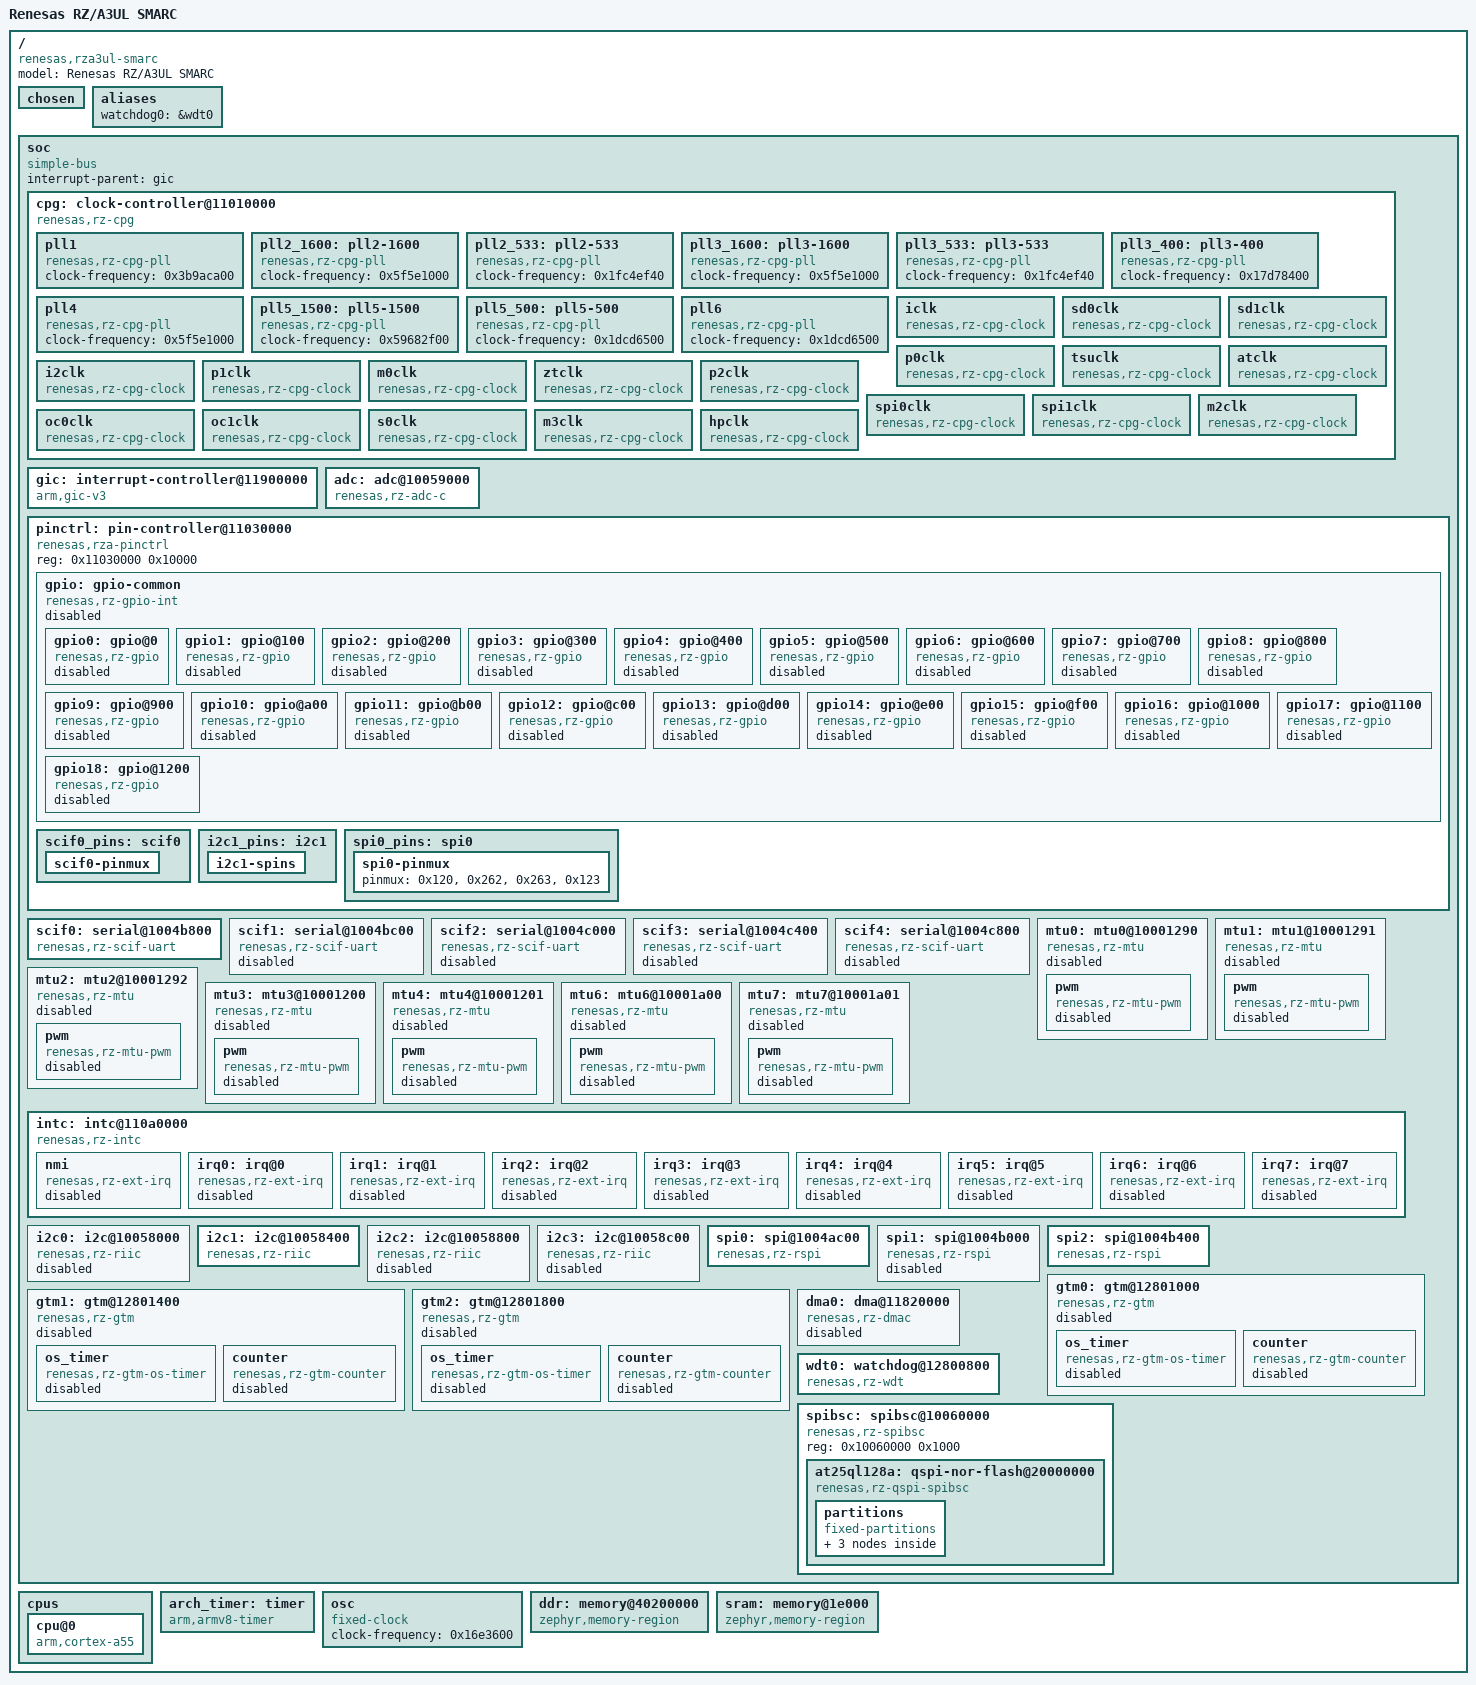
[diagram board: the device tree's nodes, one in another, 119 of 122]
/dts-v1/;

/* node '/' defined in zephyr/dts/common/skeleton.dtsi:9 */
/ {
	#address-cells = < 0x1 >;            /* in zephyr/dts/arm64/renesas/rz/rza/r9a07g063.dtsi:19 */
	#size-cells = < 0x1 >;               /* in zephyr/dts/arm64/renesas/rz/rza/r9a07g063.dtsi:20 */
	model = "Renesas RZ/A3UL SMARC";     /* in zephyr/boards/renesas/rza3ul_smarc/rza3ul_smarc.dts:16 */
	compatible = "renesas,rza3ul-smarc"; /* in zephyr/boards/renesas/rza3ul_smarc/rza3ul_smarc.dts:17 */

	/* node '/chosen' defined in zephyr/dts/common/skeleton.dtsi:13 */
	chosen {
		zephyr,sram = &ddr;                       /* in zephyr/boards/renesas/rza3ul_smarc/rza3ul_smarc.dts:20 */
		zephyr,flash = &at25ql128a;               /* in zephyr/boards/renesas/rza3ul_smarc/rza3ul_smarc.dts:21 */
		zephyr,console = &scif0;                  /* in zephyr/boards/renesas/rza3ul_smarc/rza3ul_smarc.dts:22 */
		zephyr,shell-uart = &scif0;               /* in zephyr/boards/renesas/rza3ul_smarc/rza3ul_smarc.dts:23 */
		zephyr,code-partition = &slot0_partition; /* in zephyr/boards/renesas/rza3ul_smarc/rza3ul_smarc.dts:24 */
	};

	/* node '/aliases' defined in zephyr/dts/common/skeleton.dtsi:15 */
	aliases {
		watchdog0 = &wdt0; /* in zephyr/boards/renesas/rza3ul_smarc/rza3ul_smarc.dts:28 */
	};

	/* node '/soc' defined in zephyr/dts/arm64/armv8-a.dtsi:10 */
	soc {
		#address-cells = < 0x1 >;    /* in zephyr/dts/arm64/armv8-a.dtsi:11 */
		#size-cells = < 0x1 >;       /* in zephyr/dts/arm64/armv8-a.dtsi:12 */
		compatible = "simple-bus";   /* in zephyr/dts/arm64/armv8-a.dtsi:13 */
		ranges;                      /* in zephyr/dts/arm64/armv8-a.dtsi:14 */
		interrupt-parent = < &gic >; /* in zephyr/dts/arm64/renesas/rz/rza/r9a07g063.dtsi:50 */

		/* node '/soc/clock-controller@11010000' defined in zephyr/dts/arm64/renesas/rz/rza/r9a07g063.dtsi:52 */
		cpg: clock-controller@11010000 {
			compatible = "renesas,rz-cpg"; /* in zephyr/dts/arm64/renesas/rz/rza/r9a07g063.dtsi:53 */
			reg = < 0x11010000 0x10000 >;  /* in zephyr/dts/arm64/renesas/rz/rza/r9a07g063.dtsi:54 */
			clocks = < &osc >;             /* in zephyr/dts/arm64/renesas/rz/rza/r9a07g063.dtsi:55 */
			#clock-cells = < 0x1 >;        /* in zephyr/dts/arm64/renesas/rz/rza/r9a07g063.dtsi:56 */
			status = "okay";               /* in zephyr/dts/arm64/renesas/rz/rza/r9a07g063.dtsi:57 */

			/* node '/soc/clock-controller@11010000/pll1' defined in zephyr/dts/arm64/renesas/rz/rza/r9a07g063.dtsi:59 */
			pll1: pll1 {
				compatible = "renesas,rz-cpg-pll"; /* in zephyr/dts/arm64/renesas/rz/rza/r9a07g063.dtsi:60 */
				clock-frequency = < 0x3b9aca00 >;  /* in zephyr/dts/arm64/renesas/rz/rza/r9a07g063.dtsi:61 */
				#clock-cells = < 0x1 >;            /* in zephyr/dts/arm64/renesas/rz/rza/r9a07g063.dtsi:62 */
				phandle = < 0x3 >;                 /* in zephyr/dts/arm64/renesas/rz/rza/r9a07g063.dtsi:121 */
			};

			/* node '/soc/clock-controller@11010000/pll2-1600' defined in zephyr/dts/arm64/renesas/rz/rza/r9a07g063.dtsi:65 */
			pll2_1600: pll2-1600 {
				compatible = "renesas,rz-cpg-pll"; /* in zephyr/dts/arm64/renesas/rz/rza/r9a07g063.dtsi:66 */
				clock-frequency = < 0x5f5e1000 >;  /* in zephyr/dts/arm64/renesas/rz/rza/r9a07g063.dtsi:67 */
				#clock-cells = < 0x1 >;            /* in zephyr/dts/arm64/renesas/rz/rza/r9a07g063.dtsi:68 */
				phandle = < 0x5 >;                 /* in zephyr/dts/arm64/renesas/rz/rza/r9a07g063.dtsi:135 */
			};

			/* node '/soc/clock-controller@11010000/pll2-533' defined in zephyr/dts/arm64/renesas/rz/rza/r9a07g063.dtsi:71 */
			pll2_533: pll2-533 {
				compatible = "renesas,rz-cpg-pll"; /* in zephyr/dts/arm64/renesas/rz/rza/r9a07g063.dtsi:72 */
				clock-frequency = < 0x1fc4ef40 >;  /* in zephyr/dts/arm64/renesas/rz/rza/r9a07g063.dtsi:73 */
				#clock-cells = < 0x1 >;            /* in zephyr/dts/arm64/renesas/rz/rza/r9a07g063.dtsi:74 */
				phandle = < 0x4 >;                 /* in zephyr/dts/arm64/renesas/rz/rza/r9a07g063.dtsi:128 */
			};

			/* node '/soc/clock-controller@11010000/pll3-1600' defined in zephyr/dts/arm64/renesas/rz/rza/r9a07g063.dtsi:77 */
			pll3_1600: pll3-1600 {
				compatible = "renesas,rz-cpg-pll"; /* in zephyr/dts/arm64/renesas/rz/rza/r9a07g063.dtsi:78 */
				clock-frequency = < 0x5f5e1000 >;  /* in zephyr/dts/arm64/renesas/rz/rza/r9a07g063.dtsi:79 */
				#clock-cells = < 0x1 >;            /* in zephyr/dts/arm64/renesas/rz/rza/r9a07g063.dtsi:80 */
				phandle = < 0x6 >;                 /* in zephyr/dts/arm64/renesas/rz/rza/r9a07g063.dtsi:156 */
			};

			/* node '/soc/clock-controller@11010000/pll3-533' defined in zephyr/dts/arm64/renesas/rz/rza/r9a07g063.dtsi:83 */
			pll3_533: pll3-533 {
				compatible = "renesas,rz-cpg-pll"; /* in zephyr/dts/arm64/renesas/rz/rza/r9a07g063.dtsi:84 */
				clock-frequency = < 0x1fc4ef40 >;  /* in zephyr/dts/arm64/renesas/rz/rza/r9a07g063.dtsi:85 */
				#clock-cells = < 0x1 >;            /* in zephyr/dts/arm64/renesas/rz/rza/r9a07g063.dtsi:86 */
				phandle = < 0x7 >;                 /* in zephyr/dts/arm64/renesas/rz/rza/r9a07g063.dtsi:198 */
			};

			/* node '/soc/clock-controller@11010000/pll3-400' defined in zephyr/dts/arm64/renesas/rz/rza/r9a07g063.dtsi:89 */
			pll3_400: pll3-400 {
				compatible = "renesas,rz-cpg-pll"; /* in zephyr/dts/arm64/renesas/rz/rza/r9a07g063.dtsi:90 */
				clock-frequency = < 0x17d78400 >;  /* in zephyr/dts/arm64/renesas/rz/rza/r9a07g063.dtsi:91 */
				#clock-cells = < 0x1 >;            /* in zephyr/dts/arm64/renesas/rz/rza/r9a07g063.dtsi:92 */
				phandle = < 0x8 >;                 /* in zephyr/dts/arm64/renesas/rz/rza/r9a07g063.dtsi:219 */
			};

			/* node '/soc/clock-controller@11010000/pll4' defined in zephyr/dts/arm64/renesas/rz/rza/r9a07g063.dtsi:95 */
			pll4: pll4 {
				compatible = "renesas,rz-cpg-pll"; /* in zephyr/dts/arm64/renesas/rz/rza/r9a07g063.dtsi:96 */
				clock-frequency = < 0x5f5e1000 >;  /* in zephyr/dts/arm64/renesas/rz/rza/r9a07g063.dtsi:97 */
				#clock-cells = < 0x1 >;            /* in zephyr/dts/arm64/renesas/rz/rza/r9a07g063.dtsi:98 */
				phandle = < 0x9 >;                 /* in zephyr/dts/arm64/renesas/rz/rza/r9a07g063.dtsi:233 */
			};

			/* node '/soc/clock-controller@11010000/pll5-1500' defined in zephyr/dts/arm64/renesas/rz/rza/r9a07g063.dtsi:101 */
			pll5_1500: pll5-1500 {
				compatible = "renesas,rz-cpg-pll"; /* in zephyr/dts/arm64/renesas/rz/rza/r9a07g063.dtsi:102 */
				clock-frequency = < 0x59682f00 >;  /* in zephyr/dts/arm64/renesas/rz/rza/r9a07g063.dtsi:103 */
				#clock-cells = < 0x1 >;            /* in zephyr/dts/arm64/renesas/rz/rza/r9a07g063.dtsi:104 */
				phandle = < 0xa >;                 /* in zephyr/dts/arm64/renesas/rz/rza/r9a07g063.dtsi:240 */
			};

			/* node '/soc/clock-controller@11010000/pll5-500' defined in zephyr/dts/arm64/renesas/rz/rza/r9a07g063.dtsi:107 */
			pll5_500: pll5-500 {
				compatible = "renesas,rz-cpg-pll"; /* in zephyr/dts/arm64/renesas/rz/rza/r9a07g063.dtsi:108 */
				clock-frequency = < 0x1dcd6500 >;  /* in zephyr/dts/arm64/renesas/rz/rza/r9a07g063.dtsi:109 */
				#clock-cells = < 0x1 >;            /* in zephyr/dts/arm64/renesas/rz/rza/r9a07g063.dtsi:110 */
			};

			/* node '/soc/clock-controller@11010000/pll6' defined in zephyr/dts/arm64/renesas/rz/rza/r9a07g063.dtsi:113 */
			pll6: pll6 {
				compatible = "renesas,rz-cpg-pll"; /* in zephyr/dts/arm64/renesas/rz/rza/r9a07g063.dtsi:114 */
				clock-frequency = < 0x1dcd6500 >;  /* in zephyr/dts/arm64/renesas/rz/rza/r9a07g063.dtsi:115 */
				#clock-cells = < 0x1 >;            /* in zephyr/dts/arm64/renesas/rz/rza/r9a07g063.dtsi:116 */
				phandle = < 0xb >;                 /* in zephyr/dts/arm64/renesas/rz/rza/r9a07g063.dtsi:247 */
			};

			/* node '/soc/clock-controller@11010000/iclk' defined in zephyr/dts/arm64/renesas/rz/rza/r9a07g063.dtsi:119 */
			iclk: iclk {
				compatible = "renesas,rz-cpg-clock"; /* in zephyr/dts/arm64/renesas/rz/rza/r9a07g063.dtsi:120 */
				clocks = < &pll1 0x1 >;              /* in zephyr/dts/arm64/renesas/rz/rza/r9a07g063.dtsi:121 */
				div = < 0x1 >;                       /* in zephyr/dts/arm64/renesas/rz/rza/r9a07g063.dtsi:122 */
				#clock-cells = < 0x0 >;              /* in zephyr/dts/arm64/renesas/rz/rza/r9a07g063.dtsi:123 */
			};

			/* node '/soc/clock-controller@11010000/sd0clk' defined in zephyr/dts/arm64/renesas/rz/rza/r9a07g063.dtsi:126 */
			sd0clk: sd0clk {
				compatible = "renesas,rz-cpg-clock"; /* in zephyr/dts/arm64/renesas/rz/rza/r9a07g063.dtsi:127 */
				clocks = < &pll2_533 0x2 >;          /* in zephyr/dts/arm64/renesas/rz/rza/r9a07g063.dtsi:128 */
				div = < 0x1 >;                       /* in zephyr/dts/arm64/renesas/rz/rza/r9a07g063.dtsi:129 */
				#clock-cells = < 0x0 >;              /* in zephyr/dts/arm64/renesas/rz/rza/r9a07g063.dtsi:130 */
			};

			/* node '/soc/clock-controller@11010000/sd1clk' defined in zephyr/dts/arm64/renesas/rz/rza/r9a07g063.dtsi:133 */
			sd1clk: sd1clk {
				compatible = "renesas,rz-cpg-clock"; /* in zephyr/dts/arm64/renesas/rz/rza/r9a07g063.dtsi:134 */
				clocks = < &pll2_1600 0x4 >;         /* in zephyr/dts/arm64/renesas/rz/rza/r9a07g063.dtsi:135 */
				div = < 0x1 >;                       /* in zephyr/dts/arm64/renesas/rz/rza/r9a07g063.dtsi:136 */
				#clock-cells = < 0x0 >;              /* in zephyr/dts/arm64/renesas/rz/rza/r9a07g063.dtsi:137 */
			};

			/* node '/soc/clock-controller@11010000/p0clk' defined in zephyr/dts/arm64/renesas/rz/rza/r9a07g063.dtsi:140 */
			p0clk: p0clk {
				compatible = "renesas,rz-cpg-clock"; /* in zephyr/dts/arm64/renesas/rz/rza/r9a07g063.dtsi:141 */
				clocks = < &pll2_1600 0x10 >;        /* in zephyr/dts/arm64/renesas/rz/rza/r9a07g063.dtsi:142 */
				div = < 0x1 >;                       /* in zephyr/dts/arm64/renesas/rz/rza/r9a07g063.dtsi:143 */
				#clock-cells = < 0x0 >;              /* in zephyr/dts/arm64/renesas/rz/rza/r9a07g063.dtsi:144 */
			};

			/* node '/soc/clock-controller@11010000/tsuclk' defined in zephyr/dts/arm64/renesas/rz/rza/r9a07g063.dtsi:147 */
			tsuclk: tsuclk {
				compatible = "renesas,rz-cpg-clock"; /* in zephyr/dts/arm64/renesas/rz/rza/r9a07g063.dtsi:148 */
				clocks = < &pll2_1600 0x14 >;        /* in zephyr/dts/arm64/renesas/rz/rza/r9a07g063.dtsi:149 */
				div = < 0x1 >;                       /* in zephyr/dts/arm64/renesas/rz/rza/r9a07g063.dtsi:150 */
				#clock-cells = < 0x0 >;              /* in zephyr/dts/arm64/renesas/rz/rza/r9a07g063.dtsi:151 */
			};

			/* node '/soc/clock-controller@11010000/atclk' defined in zephyr/dts/arm64/renesas/rz/rza/r9a07g063.dtsi:154 */
			atclk: atclk {
				compatible = "renesas,rz-cpg-clock"; /* in zephyr/dts/arm64/renesas/rz/rza/r9a07g063.dtsi:155 */
				clocks = < &pll3_1600 0x4 >;         /* in zephyr/dts/arm64/renesas/rz/rza/r9a07g063.dtsi:156 */
				div = < 0x1 >;                       /* in zephyr/dts/arm64/renesas/rz/rza/r9a07g063.dtsi:157 */
				#clock-cells = < 0x0 >;              /* in zephyr/dts/arm64/renesas/rz/rza/r9a07g063.dtsi:158 */
			};

			/* node '/soc/clock-controller@11010000/i2clk' defined in zephyr/dts/arm64/renesas/rz/rza/r9a07g063.dtsi:161 */
			i2clk: i2clk {
				compatible = "renesas,rz-cpg-clock"; /* in zephyr/dts/arm64/renesas/rz/rza/r9a07g063.dtsi:162 */
				clocks = < &pll3_1600 0x8 >;         /* in zephyr/dts/arm64/renesas/rz/rza/r9a07g063.dtsi:163 */
				div = < 0x1 >;                       /* in zephyr/dts/arm64/renesas/rz/rza/r9a07g063.dtsi:164 */
				#clock-cells = < 0x0 >;              /* in zephyr/dts/arm64/renesas/rz/rza/r9a07g063.dtsi:165 */
			};

			/* node '/soc/clock-controller@11010000/p1clk' defined in zephyr/dts/arm64/renesas/rz/rza/r9a07g063.dtsi:168 */
			p1clk: p1clk {
				compatible = "renesas,rz-cpg-clock"; /* in zephyr/dts/arm64/renesas/rz/rza/r9a07g063.dtsi:169 */
				clocks = < &pll3_1600 0x8 >;         /* in zephyr/dts/arm64/renesas/rz/rza/r9a07g063.dtsi:170 */
				div = < 0x1 >;                       /* in zephyr/dts/arm64/renesas/rz/rza/r9a07g063.dtsi:171 */
				#clock-cells = < 0x0 >;              /* in zephyr/dts/arm64/renesas/rz/rza/r9a07g063.dtsi:172 */
			};

			/* node '/soc/clock-controller@11010000/m0clk' defined in zephyr/dts/arm64/renesas/rz/rza/r9a07g063.dtsi:175 */
			m0clk: m0clk {
				compatible = "renesas,rz-cpg-clock"; /* in zephyr/dts/arm64/renesas/rz/rza/r9a07g063.dtsi:176 */
				clocks = < &pll3_1600 0x8 >;         /* in zephyr/dts/arm64/renesas/rz/rza/r9a07g063.dtsi:177 */
				div = < 0x1 >;                       /* in zephyr/dts/arm64/renesas/rz/rza/r9a07g063.dtsi:178 */
				#clock-cells = < 0x0 >;              /* in zephyr/dts/arm64/renesas/rz/rza/r9a07g063.dtsi:179 */
			};

			/* node '/soc/clock-controller@11010000/ztclk' defined in zephyr/dts/arm64/renesas/rz/rza/r9a07g063.dtsi:182 */
			ztclk: ztclk {
				compatible = "renesas,rz-cpg-clock"; /* in zephyr/dts/arm64/renesas/rz/rza/r9a07g063.dtsi:183 */
				clocks = < &pll3_1600 0x10 >;        /* in zephyr/dts/arm64/renesas/rz/rza/r9a07g063.dtsi:184 */
				div = < 0x1 >;                       /* in zephyr/dts/arm64/renesas/rz/rza/r9a07g063.dtsi:185 */
				#clock-cells = < 0x0 >;              /* in zephyr/dts/arm64/renesas/rz/rza/r9a07g063.dtsi:186 */
			};

			/* node '/soc/clock-controller@11010000/p2clk' defined in zephyr/dts/arm64/renesas/rz/rza/r9a07g063.dtsi:189 */
			p2clk: p2clk {
				compatible = "renesas,rz-cpg-clock"; /* in zephyr/dts/arm64/renesas/rz/rza/r9a07g063.dtsi:190 */
				clocks = < &pll3_1600 0x10 >;        /* in zephyr/dts/arm64/renesas/rz/rza/r9a07g063.dtsi:191 */
				div = < 0x1 >;                       /* in zephyr/dts/arm64/renesas/rz/rza/r9a07g063.dtsi:192 */
				#clock-cells = < 0x0 >;              /* in zephyr/dts/arm64/renesas/rz/rza/r9a07g063.dtsi:193 */
			};

			/* node '/soc/clock-controller@11010000/spi0clk' defined in zephyr/dts/arm64/renesas/rz/rza/r9a07g063.dtsi:196 */
			spi0clk: spi0clk {
				compatible = "renesas,rz-cpg-clock"; /* in zephyr/dts/arm64/renesas/rz/rza/r9a07g063.dtsi:197 */
				clocks = < &pll3_533 0x2 >;          /* in zephyr/dts/arm64/renesas/rz/rza/r9a07g063.dtsi:198 */
				div = < 0x2 >;                       /* in zephyr/dts/arm64/renesas/rz/rza/r9a07g063.dtsi:199 */
				#clock-cells = < 0x0 >;              /* in zephyr/dts/arm64/renesas/rz/rza/r9a07g063.dtsi:200 */
			};

			/* node '/soc/clock-controller@11010000/spi1clk' defined in zephyr/dts/arm64/renesas/rz/rza/r9a07g063.dtsi:203 */
			spi1clk: spi1clk {
				compatible = "renesas,rz-cpg-clock"; /* in zephyr/dts/arm64/renesas/rz/rza/r9a07g063.dtsi:204 */
				clocks = < &pll3_533 0x4 >;          /* in zephyr/dts/arm64/renesas/rz/rza/r9a07g063.dtsi:205 */
				div = < 0x2 >;                       /* in zephyr/dts/arm64/renesas/rz/rza/r9a07g063.dtsi:206 */
				#clock-cells = < 0x0 >;              /* in zephyr/dts/arm64/renesas/rz/rza/r9a07g063.dtsi:207 */
			};

			/* node '/soc/clock-controller@11010000/m2clk' defined in zephyr/dts/arm64/renesas/rz/rza/r9a07g063.dtsi:210 */
			m2clk: m2clk {
				compatible = "renesas,rz-cpg-clock"; /* in zephyr/dts/arm64/renesas/rz/rza/r9a07g063.dtsi:211 */
				clocks = < &pll3_533 0x2 >;          /* in zephyr/dts/arm64/renesas/rz/rza/r9a07g063.dtsi:212 */
				div = < 0x1 >;                       /* in zephyr/dts/arm64/renesas/rz/rza/r9a07g063.dtsi:213 */
				#clock-cells = < 0x0 >;              /* in zephyr/dts/arm64/renesas/rz/rza/r9a07g063.dtsi:214 */
			};

			/* node '/soc/clock-controller@11010000/oc0clk' defined in zephyr/dts/arm64/renesas/rz/rza/r9a07g063.dtsi:217 */
			oc0clk: oc0clk {
				compatible = "renesas,rz-cpg-clock"; /* in zephyr/dts/arm64/renesas/rz/rza/r9a07g063.dtsi:218 */
				clocks = < &pll3_400 0x2 >;          /* in zephyr/dts/arm64/renesas/rz/rza/r9a07g063.dtsi:219 */
				div = < 0x1 >;                       /* in zephyr/dts/arm64/renesas/rz/rza/r9a07g063.dtsi:220 */
				#clock-cells = < 0x0 >;              /* in zephyr/dts/arm64/renesas/rz/rza/r9a07g063.dtsi:221 */
			};

			/* node '/soc/clock-controller@11010000/oc1clk' defined in zephyr/dts/arm64/renesas/rz/rza/r9a07g063.dtsi:224 */
			oc1clk: oc1clk {
				compatible = "renesas,rz-cpg-clock"; /* in zephyr/dts/arm64/renesas/rz/rza/r9a07g063.dtsi:225 */
				clocks = < &pll3_400 0x4 >;          /* in zephyr/dts/arm64/renesas/rz/rza/r9a07g063.dtsi:226 */
				div = < 0x1 >;                       /* in zephyr/dts/arm64/renesas/rz/rza/r9a07g063.dtsi:227 */
				#clock-cells = < 0x0 >;              /* in zephyr/dts/arm64/renesas/rz/rza/r9a07g063.dtsi:228 */
			};

			/* node '/soc/clock-controller@11010000/s0clk' defined in zephyr/dts/arm64/renesas/rz/rza/r9a07g063.dtsi:231 */
			s0clk: s0clk {
				compatible = "renesas,rz-cpg-clock"; /* in zephyr/dts/arm64/renesas/rz/rza/r9a07g063.dtsi:232 */
				clocks = < &pll4 0x2 >;              /* in zephyr/dts/arm64/renesas/rz/rza/r9a07g063.dtsi:233 */
				div = < 0x1 >;                       /* in zephyr/dts/arm64/renesas/rz/rza/r9a07g063.dtsi:234 */
				#clock-cells = < 0x0 >;              /* in zephyr/dts/arm64/renesas/rz/rza/r9a07g063.dtsi:235 */
			};

			/* node '/soc/clock-controller@11010000/m3clk' defined in zephyr/dts/arm64/renesas/rz/rza/r9a07g063.dtsi:238 */
			m3clk: m3clk {
				compatible = "renesas,rz-cpg-clock"; /* in zephyr/dts/arm64/renesas/rz/rza/r9a07g063.dtsi:239 */
				clocks = < &pll5_1500 0x1 >;         /* in zephyr/dts/arm64/renesas/rz/rza/r9a07g063.dtsi:240 */
				div = < 0x2 >;                       /* in zephyr/dts/arm64/renesas/rz/rza/r9a07g063.dtsi:241 */
				#clock-cells = < 0x0 >;              /* in zephyr/dts/arm64/renesas/rz/rza/r9a07g063.dtsi:242 */
			};

			/* node '/soc/clock-controller@11010000/hpclk' defined in zephyr/dts/arm64/renesas/rz/rza/r9a07g063.dtsi:245 */
			hpclk: hpclk {
				compatible = "renesas,rz-cpg-clock"; /* in zephyr/dts/arm64/renesas/rz/rza/r9a07g063.dtsi:246 */
				clocks = < &pll6 0x2 >;              /* in zephyr/dts/arm64/renesas/rz/rza/r9a07g063.dtsi:247 */
				div = < 0x1 >;                       /* in zephyr/dts/arm64/renesas/rz/rza/r9a07g063.dtsi:248 */
				#clock-cells = < 0x0 >;              /* in zephyr/dts/arm64/renesas/rz/rza/r9a07g063.dtsi:249 */
			};
		};

		/* node '/soc/interrupt-controller@11900000' defined in zephyr/dts/arm64/renesas/rz/rza/r9a07g063.dtsi:253 */
		gic: interrupt-controller@11900000 {
			compatible = "arm,gic-v3",
			             "arm,gic";       /* in zephyr/dts/arm64/renesas/rz/rza/r9a07g063.dtsi:254 */
			reg = < 0x11900000 0x10000 >,
			      < 0x11940000 0x20000 >; /* in zephyr/dts/arm64/renesas/rz/rza/r9a07g063.dtsi:255 */
			interrupt-controller;         /* in zephyr/dts/arm64/renesas/rz/rza/r9a07g063.dtsi:257 */
			#interrupt-cells = < 0x4 >;   /* in zephyr/dts/arm64/renesas/rz/rza/r9a07g063.dtsi:258 */
			status = "okay";              /* in zephyr/dts/arm64/renesas/rz/rza/r9a07g063.dtsi:259 */
			phandle = < 0x1 >;            /* in zephyr/dts/arm64/renesas/rz/rza/r9a07g063.dtsi:50 */
		};

		/* node '/soc/adc@10059000' defined in zephyr/dts/arm64/renesas/rz/rza/r9a07g063.dtsi:262 */
		adc: adc@10059000 {
			compatible = "renesas,rz-adc-c";     /* in zephyr/dts/arm64/renesas/rz/rza/r9a07g063.dtsi:263 */
			reg = < 0x10059000 0x400 >;          /* in zephyr/dts/arm64/renesas/rz/rza/r9a07g063.dtsi:264 */
			interrupts = < 0x0 0x15b 0x4 0xa0 >; /* in zephyr/dts/arm64/renesas/rz/rza/r9a07g063.dtsi:265 */
			interrupt-names = "scanend";         /* in zephyr/dts/arm64/renesas/rz/rza/r9a07g063.dtsi:266 */
			#io-channel-cells = < 0x1 >;         /* in zephyr/dts/arm64/renesas/rz/rza/r9a07g063.dtsi:267 */
			vref-mv = < 0x708 >;                 /* in zephyr/dts/arm64/renesas/rz/rza/r9a07g063.dtsi:268 */
			channel-available-mask = < 0x3 >;    /* in zephyr/dts/arm64/renesas/rz/rza/r9a07g063.dtsi:269 */
			status = "okay";                     /* in zephyr/boards/renesas/rza3ul_smarc/rza3ul_smarc.dts:53 */
		};

		/* node '/soc/pin-controller@11030000' defined in zephyr/dts/arm64/renesas/rz/rza/r9a07g063.dtsi:273 */
		pinctrl: pin-controller@11030000 {
			compatible = "renesas,rza-pinctrl"; /* in zephyr/dts/arm64/renesas/rz/rza/r9a07g063.dtsi:274 */
			reg = < 0x11030000 0x10000 >;       /* in zephyr/dts/arm64/renesas/rz/rza/r9a07g063.dtsi:275 */
			reg-names = "pinctrl";              /* in zephyr/dts/arm64/renesas/rz/rza/r9a07g063.dtsi:276 */

			/* node '/soc/pin-controller@11030000/gpio-common' defined in zephyr/dts/arm64/renesas/rz/rza/r9a07g063.dtsi:278 */
			gpio: gpio-common {
				compatible = "renesas,rz-gpio-int";  /* in zephyr/dts/arm64/renesas/rz/rza/r9a07g063.dtsi:279 */
				interrupts = < 0x0 0x1bc 0x2 0xa0 >,
				             < 0x0 0x1bd 0x2 0xa0 >,
				             < 0x0 0x1be 0x2 0xa0 >,
				             < 0x0 0x1bf 0x2 0xa0 >,
				             < 0x0 0x1c0 0x2 0xa0 >,
				             < 0x0 0x1c1 0x2 0xa0 >,
				             < 0x0 0x1c2 0x2 0xa0 >,
				             < 0x0 0x1c3 0x2 0xa0 >,
				             < 0x0 0x1c4 0x2 0xa0 >,
				             < 0x0 0x1c5 0x2 0xa0 >,
				             < 0x0 0x1c6 0x2 0xa0 >,
				             < 0x0 0x1c7 0x2 0xa0 >,
				             < 0x0 0x1c8 0x2 0xa0 >,
				             < 0x0 0x1c9 0x2 0xa0 >,
				             < 0x0 0x1ca 0x2 0xa0 >,
				             < 0x0 0x1cb 0x2 0xa0 >,
				             < 0x0 0x1cc 0x2 0xa0 >,
				             < 0x0 0x1cd 0x2 0xa0 >,
				             < 0x0 0x1ce 0x2 0xa0 >,
				             < 0x0 0x1cf 0x2 0xa0 >,
				             < 0x0 0x1d0 0x2 0xa0 >,
				             < 0x0 0x1d1 0x2 0xa0 >,
				             < 0x0 0x1d2 0x2 0xa0 >,
				             < 0x0 0x1d3 0x2 0xa0 >,
				             < 0x0 0x1d4 0x2 0xa0 >,
				             < 0x0 0x1d5 0x2 0xa0 >,
				             < 0x0 0x1d6 0x2 0xa0 >,
				             < 0x0 0x1d7 0x2 0xa0 >,
				             < 0x0 0x1d8 0x2 0xa0 >,
				             < 0x0 0x1d9 0x2 0xa0 >,
				             < 0x0 0x1da 0x2 0xa0 >,
				             < 0x0 0x1db 0x2 0xa0 >; /* in zephyr/dts/arm64/renesas/rz/rza/r9a07g063.dtsi:280 */
				#address-cells = < 0x1 >;            /* in zephyr/dts/arm64/renesas/rz/rza/r9a07g063.dtsi:312 */
				#size-cells = < 0x0 >;               /* in zephyr/dts/arm64/renesas/rz/rza/r9a07g063.dtsi:313 */
				status = "disabled";                 /* in zephyr/dts/arm64/renesas/rz/rza/r9a07g063.dtsi:314 */

				/* node '/soc/pin-controller@11030000/gpio-common/gpio@0' defined in zephyr/dts/arm64/renesas/rz/rza/r9a07g063.dtsi:316 */
				gpio0: gpio@0 {
					compatible = "renesas,rz-gpio"; /* in zephyr/dts/arm64/renesas/rz/rza/r9a07g063.dtsi:317 */
					gpio-controller;                /* in zephyr/dts/arm64/renesas/rz/rza/r9a07g063.dtsi:318 */
					#gpio-cells = < 0x2 >;          /* in zephyr/dts/arm64/renesas/rz/rza/r9a07g063.dtsi:319 */
					ngpios = < 0x4 >;               /* in zephyr/dts/arm64/renesas/rz/rza/r9a07g063.dtsi:320 */
					reg = < 0x0 >;                  /* in zephyr/dts/arm64/renesas/rz/rza/r9a07g063.dtsi:321 */
					status = "disabled";            /* in zephyr/dts/arm64/renesas/rz/rza/r9a07g063.dtsi:322 */
				};

				/* node '/soc/pin-controller@11030000/gpio-common/gpio@100' defined in zephyr/dts/arm64/renesas/rz/rza/r9a07g063.dtsi:325 */
				gpio1: gpio@100 {
					compatible = "renesas,rz-gpio"; /* in zephyr/dts/arm64/renesas/rz/rza/r9a07g063.dtsi:326 */
					gpio-controller;                /* in zephyr/dts/arm64/renesas/rz/rza/r9a07g063.dtsi:327 */
					#gpio-cells = < 0x2 >;          /* in zephyr/dts/arm64/renesas/rz/rza/r9a07g063.dtsi:328 */
					ngpios = < 0x5 >;               /* in zephyr/dts/arm64/renesas/rz/rza/r9a07g063.dtsi:329 */
					reg = < 0x100 >;                /* in zephyr/dts/arm64/renesas/rz/rza/r9a07g063.dtsi:330 */
					status = "disabled";            /* in zephyr/dts/arm64/renesas/rz/rza/r9a07g063.dtsi:331 */
				};

				/* node '/soc/pin-controller@11030000/gpio-common/gpio@200' defined in zephyr/dts/arm64/renesas/rz/rza/r9a07g063.dtsi:334 */
				gpio2: gpio@200 {
					compatible = "renesas,rz-gpio"; /* in zephyr/dts/arm64/renesas/rz/rza/r9a07g063.dtsi:335 */
					gpio-controller;                /* in zephyr/dts/arm64/renesas/rz/rza/r9a07g063.dtsi:336 */
					#gpio-cells = < 0x2 >;          /* in zephyr/dts/arm64/renesas/rz/rza/r9a07g063.dtsi:337 */
					ngpios = < 0x4 >;               /* in zephyr/dts/arm64/renesas/rz/rza/r9a07g063.dtsi:338 */
					reg = < 0x200 >;                /* in zephyr/dts/arm64/renesas/rz/rza/r9a07g063.dtsi:339 */
					status = "disabled";            /* in zephyr/dts/arm64/renesas/rz/rza/r9a07g063.dtsi:340 */
				};

				/* node '/soc/pin-controller@11030000/gpio-common/gpio@300' defined in zephyr/dts/arm64/renesas/rz/rza/r9a07g063.dtsi:343 */
				gpio3: gpio@300 {
					compatible = "renesas,rz-gpio"; /* in zephyr/dts/arm64/renesas/rz/rza/r9a07g063.dtsi:344 */
					gpio-controller;                /* in zephyr/dts/arm64/renesas/rz/rza/r9a07g063.dtsi:345 */
					#gpio-cells = < 0x2 >;          /* in zephyr/dts/arm64/renesas/rz/rza/r9a07g063.dtsi:346 */
					ngpios = < 0x4 >;               /* in zephyr/dts/arm64/renesas/rz/rza/r9a07g063.dtsi:347 */
					reg = < 0x300 >;                /* in zephyr/dts/arm64/renesas/rz/rza/r9a07g063.dtsi:348 */
					status = "disabled";            /* in zephyr/dts/arm64/renesas/rz/rza/r9a07g063.dtsi:349 */
				};

				/* node '/soc/pin-controller@11030000/gpio-common/gpio@400' defined in zephyr/dts/arm64/renesas/rz/rza/r9a07g063.dtsi:352 */
				gpio4: gpio@400 {
					compatible = "renesas,rz-gpio"; /* in zephyr/dts/arm64/renesas/rz/rza/r9a07g063.dtsi:353 */
					gpio-controller;                /* in zephyr/dts/arm64/renesas/rz/rza/r9a07g063.dtsi:354 */
					#gpio-cells = < 0x2 >;          /* in zephyr/dts/arm64/renesas/rz/rza/r9a07g063.dtsi:355 */
					ngpios = < 0x6 >;               /* in zephyr/dts/arm64/renesas/rz/rza/r9a07g063.dtsi:356 */
					reg = < 0x400 >;                /* in zephyr/dts/arm64/renesas/rz/rza/r9a07g063.dtsi:357 */
					status = "disabled";            /* in zephyr/dts/arm64/renesas/rz/rza/r9a07g063.dtsi:358 */
				};

				/* node '/soc/pin-controller@11030000/gpio-common/gpio@500' defined in zephyr/dts/arm64/renesas/rz/rza/r9a07g063.dtsi:361 */
				gpio5: gpio@500 {
					compatible = "renesas,rz-gpio"; /* in zephyr/dts/arm64/renesas/rz/rza/r9a07g063.dtsi:362 */
					gpio-controller;                /* in zephyr/dts/arm64/renesas/rz/rza/r9a07g063.dtsi:363 */
					#gpio-cells = < 0x2 >;          /* in zephyr/dts/arm64/renesas/rz/rza/r9a07g063.dtsi:364 */
					ngpios = < 0x5 >;               /* in zephyr/dts/arm64/renesas/rz/rza/r9a07g063.dtsi:365 */
					reg = < 0x500 >;                /* in zephyr/dts/arm64/renesas/rz/rza/r9a07g063.dtsi:366 */
					status = "disabled";            /* in zephyr/dts/arm64/renesas/rz/rza/r9a07g063.dtsi:367 */
				};

				/* node '/soc/pin-controller@11030000/gpio-common/gpio@600' defined in zephyr/dts/arm64/renesas/rz/rza/r9a07g063.dtsi:370 */
				gpio6: gpio@600 {
					compatible = "renesas,rz-gpio"; /* in zephyr/dts/arm64/renesas/rz/rza/r9a07g063.dtsi:371 */
					gpio-controller;                /* in zephyr/dts/arm64/renesas/rz/rza/r9a07g063.dtsi:372 */
					#gpio-cells = < 0x2 >;          /* in zephyr/dts/arm64/renesas/rz/rza/r9a07g063.dtsi:373 */
					ngpios = < 0x5 >;               /* in zephyr/dts/arm64/renesas/rz/rza/r9a07g063.dtsi:374 */
					reg = < 0x600 >;                /* in zephyr/dts/arm64/renesas/rz/rza/r9a07g063.dtsi:375 */
					status = "disabled";            /* in zephyr/dts/arm64/renesas/rz/rza/r9a07g063.dtsi:376 */
				};

				/* node '/soc/pin-controller@11030000/gpio-common/gpio@700' defined in zephyr/dts/arm64/renesas/rz/rza/r9a07g063.dtsi:379 */
				gpio7: gpio@700 {
					compatible = "renesas,rz-gpio"; /* in zephyr/dts/arm64/renesas/rz/rza/r9a07g063.dtsi:380 */
					gpio-controller;                /* in zephyr/dts/arm64/renesas/rz/rza/r9a07g063.dtsi:381 */
					#gpio-cells = < 0x2 >;          /* in zephyr/dts/arm64/renesas/rz/rza/r9a07g063.dtsi:382 */
					ngpios = < 0x5 >;               /* in zephyr/dts/arm64/renesas/rz/rza/r9a07g063.dtsi:383 */
					reg = < 0x700 >;                /* in zephyr/dts/arm64/renesas/rz/rza/r9a07g063.dtsi:384 */
					status = "disabled";            /* in zephyr/dts/arm64/renesas/rz/rza/r9a07g063.dtsi:385 */
				};

				/* node '/soc/pin-controller@11030000/gpio-common/gpio@800' defined in zephyr/dts/arm64/renesas/rz/rza/r9a07g063.dtsi:388 */
				gpio8: gpio@800 {
					compatible = "renesas,rz-gpio"; /* in zephyr/dts/arm64/renesas/rz/rza/r9a07g063.dtsi:389 */
					gpio-controller;                /* in zephyr/dts/arm64/renesas/rz/rza/r9a07g063.dtsi:390 */
					#gpio-cells = < 0x2 >;          /* in zephyr/dts/arm64/renesas/rz/rza/r9a07g063.dtsi:391 */
					ngpios = < 0x5 >;               /* in zephyr/dts/arm64/renesas/rz/rza/r9a07g063.dtsi:392 */
					reg = < 0x800 >;                /* in zephyr/dts/arm64/renesas/rz/rza/r9a07g063.dtsi:393 */
					status = "disabled";            /* in zephyr/dts/arm64/renesas/rz/rza/r9a07g063.dtsi:394 */
				};

				/* node '/soc/pin-controller@11030000/gpio-common/gpio@900' defined in zephyr/dts/arm64/renesas/rz/rza/r9a07g063.dtsi:397 */
				gpio9: gpio@900 {
					compatible = "renesas,rz-gpio"; /* in zephyr/dts/arm64/renesas/rz/rza/r9a07g063.dtsi:398 */
					gpio-controller;                /* in zephyr/dts/arm64/renesas/rz/rza/r9a07g063.dtsi:399 */
					#gpio-cells = < 0x2 >;          /* in zephyr/dts/arm64/renesas/rz/rza/r9a07g063.dtsi:400 */
					ngpios = < 0x4 >;               /* in zephyr/dts/arm64/renesas/rz/rza/r9a07g063.dtsi:401 */
					reg = < 0x900 >;                /* in zephyr/dts/arm64/renesas/rz/rza/r9a07g063.dtsi:402 */
					status = "disabled";            /* in zephyr/dts/arm64/renesas/rz/rza/r9a07g063.dtsi:403 */
				};

				/* node '/soc/pin-controller@11030000/gpio-common/gpio@a00' defined in zephyr/dts/arm64/renesas/rz/rza/r9a07g063.dtsi:406 */
				gpio10: gpio@a00 {
					compatible = "renesas,rz-gpio"; /* in zephyr/dts/arm64/renesas/rz/rza/r9a07g063.dtsi:407 */
					gpio-controller;                /* in zephyr/dts/arm64/renesas/rz/rza/r9a07g063.dtsi:408 */
					#gpio-cells = < 0x2 >;          /* in zephyr/dts/arm64/renesas/rz/rza/r9a07g063.dtsi:409 */
					ngpios = < 0x5 >;               /* in zephyr/dts/arm64/renesas/rz/rza/r9a07g063.dtsi:410 */
					reg = < 0xa00 >;                /* in zephyr/dts/arm64/renesas/rz/rza/r9a07g063.dtsi:411 */
					status = "disabled";            /* in zephyr/dts/arm64/renesas/rz/rza/r9a07g063.dtsi:412 */
				};

				/* node '/soc/pin-controller@11030000/gpio-common/gpio@b00' defined in zephyr/dts/arm64/renesas/rz/rza/r9a07g063.dtsi:415 */
				gpio11: gpio@b00 {
					compatible = "renesas,rz-gpio"; /* in zephyr/dts/arm64/renesas/rz/rza/r9a07g063.dtsi:416 */
					gpio-controller;                /* in zephyr/dts/arm64/renesas/rz/rza/r9a07g063.dtsi:417 */
					#gpio-cells = < 0x2 >;          /* in zephyr/dts/arm64/renesas/rz/rza/r9a07g063.dtsi:418 */
					ngpios = < 0x4 >;               /* in zephyr/dts/arm64/renesas/rz/rza/r9a07g063.dtsi:419 */
					reg = < 0xb00 >;                /* in zephyr/dts/arm64/renesas/rz/rza/r9a07g063.dtsi:420 */
					status = "disabled";            /* in zephyr/dts/arm64/renesas/rz/rza/r9a07g063.dtsi:421 */
				};

				/* node '/soc/pin-controller@11030000/gpio-common/gpio@c00' defined in zephyr/dts/arm64/renesas/rz/rza/r9a07g063.dtsi:424 */
				gpio12: gpio@c00 {
					compatible = "renesas,rz-gpio"; /* in zephyr/dts/arm64/renesas/rz/rza/r9a07g063.dtsi:425 */
					gpio-controller;                /* in zephyr/dts/arm64/renesas/rz/rza/r9a07g063.dtsi:426 */
					#gpio-cells = < 0x2 >;          /* in zephyr/dts/arm64/renesas/rz/rza/r9a07g063.dtsi:427 */
					ngpios = < 0x2 >;               /* in zephyr/dts/arm64/renesas/rz/rza/r9a07g063.dtsi:428 */
					reg = < 0xc00 >;                /* in zephyr/dts/arm64/renesas/rz/rza/r9a07g063.dtsi:429 */
					status = "disabled";            /* in zephyr/dts/arm64/renesas/rz/rza/r9a07g063.dtsi:430 */
				};

				/* node '/soc/pin-controller@11030000/gpio-common/gpio@d00' defined in zephyr/dts/arm64/renesas/rz/rza/r9a07g063.dtsi:433 */
				gpio13: gpio@d00 {
					compatible = "renesas,rz-gpio"; /* in zephyr/dts/arm64/renesas/rz/rza/r9a07g063.dtsi:434 */
					gpio-controller;                /* in zephyr/dts/arm64/renesas/rz/rza/r9a07g063.dtsi:435 */
					#gpio-cells = < 0x2 >;          /* in zephyr/dts/arm64/renesas/rz/rza/r9a07g063.dtsi:436 */
					ngpios = < 0x5 >;               /* in zephyr/dts/arm64/renesas/rz/rza/r9a07g063.dtsi:437 */
					reg = < 0xd00 >;                /* in zephyr/dts/arm64/renesas/rz/rza/r9a07g063.dtsi:438 */
					status = "disabled";            /* in zephyr/dts/arm64/renesas/rz/rza/r9a07g063.dtsi:439 */
				};

				/* node '/soc/pin-controller@11030000/gpio-common/gpio@e00' defined in zephyr/dts/arm64/renesas/rz/rza/r9a07g063.dtsi:442 */
				gpio14: gpio@e00 {
					compatible = "renesas,rz-gpio"; /* in zephyr/dts/arm64/renesas/rz/rza/r9a07g063.dtsi:443 */
					gpio-controller;                /* in zephyr/dts/arm64/renesas/rz/rza/r9a07g063.dtsi:444 */
					#gpio-cells = < 0x2 >;          /* in zephyr/dts/arm64/renesas/rz/rza/r9a07g063.dtsi:445 */
					ngpios = < 0x3 >;               /* in zephyr/dts/arm64/renesas/rz/rza/r9a07g063.dtsi:446 */
					reg = < 0xe00 >;                /* in zephyr/dts/arm64/renesas/rz/rza/r9a07g063.dtsi:447 */
					status = "disabled";            /* in zephyr/dts/arm64/renesas/rz/rza/r9a07g063.dtsi:448 */
				};

				/* node '/soc/pin-controller@11030000/gpio-common/gpio@f00' defined in zephyr/dts/arm64/renesas/rz/rza/r9a07g063.dtsi:451 */
				gpio15: gpio@f00 {
					compatible = "renesas,rz-gpio"; /* in zephyr/dts/arm64/renesas/rz/rza/r9a07g063.dtsi:452 */
					gpio-controller;                /* in zephyr/dts/arm64/renesas/rz/rza/r9a07g063.dtsi:453 */
					#gpio-cells = < 0x2 >;          /* in zephyr/dts/arm64/renesas/rz/rza/r9a07g063.dtsi:454 */
					ngpios = < 0x4 >;               /* in zephyr/dts/arm64/renesas/rz/rza/r9a07g063.dtsi:455 */
					reg = < 0xf00 >;                /* in zephyr/dts/arm64/renesas/rz/rza/r9a07g063.dtsi:456 */
					status = "disabled";            /* in zephyr/dts/arm64/renesas/rz/rza/r9a07g063.dtsi:457 */
				};

				/* node '/soc/pin-controller@11030000/gpio-common/gpio@1000' defined in zephyr/dts/arm64/renesas/rz/rza/r9a07g063.dtsi:460 */
				gpio16: gpio@1000 {
					compatible = "renesas,rz-gpio"; /* in zephyr/dts/arm64/renesas/rz/rza/r9a07g063.dtsi:461 */
					gpio-controller;                /* in zephyr/dts/arm64/renesas/rz/rza/r9a07g063.dtsi:462 */
					#gpio-cells = < 0x2 >;          /* in zephyr/dts/arm64/renesas/rz/rza/r9a07g063.dtsi:463 */
					ngpios = < 0x2 >;               /* in zephyr/dts/arm64/renesas/rz/rza/r9a07g063.dtsi:464 */
					reg = < 0x1000 >;               /* in zephyr/dts/arm64/renesas/rz/rza/r9a07g063.dtsi:465 */
					status = "disabled";            /* in zephyr/dts/arm64/renesas/rz/rza/r9a07g063.dtsi:466 */
				};

				/* node '/soc/pin-controller@11030000/gpio-common/gpio@1100' defined in zephyr/dts/arm64/renesas/rz/rza/r9a07g063.dtsi:469 */
				gpio17: gpio@1100 {
					compatible = "renesas,rz-gpio"; /* in zephyr/dts/arm64/renesas/rz/rza/r9a07g063.dtsi:470 */
					gpio-controller;                /* in zephyr/dts/arm64/renesas/rz/rza/r9a07g063.dtsi:471 */
					#gpio-cells = < 0x2 >;          /* in zephyr/dts/arm64/renesas/rz/rza/r9a07g063.dtsi:472 */
					ngpios = < 0x4 >;               /* in zephyr/dts/arm64/renesas/rz/rza/r9a07g063.dtsi:473 */
					reg = < 0x1100 >;               /* in zephyr/dts/arm64/renesas/rz/rza/r9a07g063.dtsi:474 */
					status = "disabled";            /* in zephyr/dts/arm64/renesas/rz/rza/r9a07g063.dtsi:475 */
				};

				/* node '/soc/pin-controller@11030000/gpio-common/gpio@1200' defined in zephyr/dts/arm64/renesas/rz/rza/r9a07g063.dtsi:478 */
				gpio18: gpio@1200 {
					compatible = "renesas,rz-gpio"; /* in zephyr/dts/arm64/renesas/rz/rza/r9a07g063.dtsi:479 */
					gpio-controller;                /* in zephyr/dts/arm64/renesas/rz/rza/r9a07g063.dtsi:480 */
					#gpio-cells = < 0x2 >;          /* in zephyr/dts/arm64/renesas/rz/rza/r9a07g063.dtsi:481 */
					ngpios = < 0x6 >;               /* in zephyr/dts/arm64/renesas/rz/rza/r9a07g063.dtsi:482 */
					reg = < 0x1200 >;               /* in zephyr/dts/arm64/renesas/rz/rza/r9a07g063.dtsi:483 */
					status = "disabled";            /* in zephyr/dts/arm64/renesas/rz/rza/r9a07g063.dtsi:484 */
				};
			};

			/* node '/soc/pin-controller@11030000/scif0' defined in zephyr/boards/renesas/rza3ul_smarc/rza3ul_smarc-pinctrl.dtsi:10 */
			scif0_pins: scif0 {
				phandle = < 0xc >; /* in zephyr/boards/renesas/rza3ul_smarc/rza3ul_smarc.dts:47 */

				/* node '/soc/pin-controller@11030000/scif0/scif0-pinmux' defined in zephyr/boards/renesas/rza3ul_smarc/rza3ul_smarc-pinctrl.dtsi:11 */
				scif0-pinmux {
					pinmux = < 0x663 >,
					         < 0x664 >;       /* in zephyr/boards/renesas/rza3ul_smarc/rza3ul_smarc-pinctrl.dtsi:12 */
					drive-strength = < 0x1 >; /* in zephyr/boards/renesas/rza3ul_smarc/rza3ul_smarc-pinctrl.dtsi:14 */
					slew-rate = "fast";       /* in zephyr/boards/renesas/rza3ul_smarc/rza3ul_smarc-pinctrl.dtsi:15 */
				};
			};

			/* node '/soc/pin-controller@11030000/i2c1' defined in zephyr/boards/renesas/rza3ul_smarc/rza3ul_smarc-pinctrl.dtsi:31 */
			i2c1_pins: i2c1 {
				phandle = < 0xd >; /* in zephyr/boards/renesas/rza3ul_smarc/rza3ul_smarc.dts:57 */

				/* node '/soc/pin-controller@11030000/i2c1/i2c1-spins' defined in zephyr/boards/renesas/rza3ul_smarc/rza3ul_smarc-pinctrl.dtsi:32 */
				i2c1-spins {
					pins = < 0xffff0e02 >,
					       < 0xffff0e03 >; /* in zephyr/boards/renesas/rza3ul_smarc/rza3ul_smarc-pinctrl.dtsi:33 */
					input-enable;          /* in zephyr/boards/renesas/rza3ul_smarc/rza3ul_smarc-pinctrl.dtsi:34 */
				};
			};

			/* node '/soc/pin-controller@11030000/spi0' defined in zephyr/boards/renesas/rza3ul_smarc/rza3ul_smarc-pinctrl.dtsi:38 */
			spi0_pins: spi0 {
				phandle = < 0xe >; /* in zephyr/boards/renesas/rza3ul_smarc/rza3ul_smarc.dts:63 */

				/* node '/soc/pin-controller@11030000/spi0/spi0-pinmux' defined in zephyr/boards/renesas/rza3ul_smarc/rza3ul_smarc-pinctrl.dtsi:39 */
				spi0-pinmux {
					pinmux = < 0x120 >,
					         < 0x262 >,
					         < 0x263 >,
					         < 0x123 >; /* in zephyr/boards/renesas/rza3ul_smarc/rza3ul_smarc-pinctrl.dtsi:40 */
				};
			};
		};

		/* node '/soc/serial@1004b800' defined in zephyr/dts/arm64/renesas/rz/rza/r9a07g063.dtsi:489 */
		scif0: serial@1004b800 {
			compatible = "renesas,rz-scif-uart"; /* in zephyr/dts/arm64/renesas/rz/rza/r9a07g063.dtsi:490 */
			channel = < 0x0 >;                   /* in zephyr/dts/arm64/renesas/rz/rza/r9a07g063.dtsi:491 */
			reg = < 0x1004b800 0x400 >;          /* in zephyr/dts/arm64/renesas/rz/rza/r9a07g063.dtsi:492 */
			interrupts = < 0x0 0x17c 0x2 0xa0 >,
			             < 0x0 0x17d 0x2 0xa0 >,
			             < 0x0 0x17e 0x2 0xa0 >,
			             < 0x0 0x17f 0x2 0xa0 >,
			             < 0x0 0x180 0x2 0xa0 >; /* in zephyr/dts/arm64/renesas/rz/rza/r9a07g063.dtsi:493 */
			interrupt-names = "eri",
			                  "bri",
			                  "rxi",
			                  "txi",
			                  "tei";             /* in zephyr/dts/arm64/renesas/rz/rza/r9a07g063.dtsi:498 */
			current-speed = < 0x1c200 >;         /* in zephyr/boards/renesas/rza3ul_smarc/rza3ul_smarc.dts:46 */
			pinctrl-0 = < &scif0_pins >;         /* in zephyr/boards/renesas/rza3ul_smarc/rza3ul_smarc.dts:47 */
			pinctrl-names = "default";           /* in zephyr/boards/renesas/rza3ul_smarc/rza3ul_smarc.dts:48 */
			status = "okay";                     /* in zephyr/boards/renesas/rza3ul_smarc/rza3ul_smarc.dts:49 */
		};

		/* node '/soc/serial@1004bc00' defined in zephyr/dts/arm64/renesas/rz/rza/r9a07g063.dtsi:502 */
		scif1: serial@1004bc00 {
			compatible = "renesas,rz-scif-uart"; /* in zephyr/dts/arm64/renesas/rz/rza/r9a07g063.dtsi:503 */
			channel = < 0x1 >;                   /* in zephyr/dts/arm64/renesas/rz/rza/r9a07g063.dtsi:504 */
			reg = < 0x1004bc00 0x400 >;          /* in zephyr/dts/arm64/renesas/rz/rza/r9a07g063.dtsi:505 */
			interrupts = < 0x0 0x181 0x2 0xa0 >,
			             < 0x0 0x182 0x2 0xa0 >,
			             < 0x0 0x183 0x2 0xa0 >,
			             < 0x0 0x184 0x2 0xa0 >,
			             < 0x0 0x185 0x2 0xa0 >; /* in zephyr/dts/arm64/renesas/rz/rza/r9a07g063.dtsi:506 */
			interrupt-names = "eri",
			                  "bri",
			                  "rxi",
			                  "txi",
			                  "tei";             /* in zephyr/dts/arm64/renesas/rz/rza/r9a07g063.dtsi:511 */
			status = "disabled";                 /* in zephyr/dts/arm64/renesas/rz/rza/r9a07g063.dtsi:512 */
		};

		/* node '/soc/serial@1004c000' defined in zephyr/dts/arm64/renesas/rz/rza/r9a07g063.dtsi:515 */
		scif2: serial@1004c000 {
			compatible = "renesas,rz-scif-uart"; /* in zephyr/dts/arm64/renesas/rz/rza/r9a07g063.dtsi:516 */
			channel = < 0x2 >;                   /* in zephyr/dts/arm64/renesas/rz/rza/r9a07g063.dtsi:517 */
			reg = < 0x1004c000 0x400 >;          /* in zephyr/dts/arm64/renesas/rz/rza/r9a07g063.dtsi:518 */
			interrupts = < 0x0 0x186 0x2 0xa0 >,
			             < 0x0 0x187 0x2 0xa0 >,
			             < 0x0 0x188 0x2 0xa0 >,
			             < 0x0 0x189 0x2 0xa0 >,
			             < 0x0 0x18a 0x2 0xa0 >; /* in zephyr/dts/arm64/renesas/rz/rza/r9a07g063.dtsi:519 */
			interrupt-names = "eri",
			                  "bri",
			                  "rxi",
			                  "txi",
			                  "tei";             /* in zephyr/dts/arm64/renesas/rz/rza/r9a07g063.dtsi:524 */
			status = "disabled";                 /* in zephyr/dts/arm64/renesas/rz/rza/r9a07g063.dtsi:525 */
		};

		/* node '/soc/serial@1004c400' defined in zephyr/dts/arm64/renesas/rz/rza/r9a07g063.dtsi:528 */
		scif3: serial@1004c400 {
			compatible = "renesas,rz-scif-uart"; /* in zephyr/dts/arm64/renesas/rz/rza/r9a07g063.dtsi:529 */
			channel = < 0x3 >;                   /* in zephyr/dts/arm64/renesas/rz/rza/r9a07g063.dtsi:530 */
			reg = < 0x1004c400 0x400 >;          /* in zephyr/dts/arm64/renesas/rz/rza/r9a07g063.dtsi:531 */
			interrupts = < 0x0 0x18b 0x2 0xa0 >,
			             < 0x0 0x18c 0x2 0xa0 >,
			             < 0x0 0x18d 0x2 0xa0 >,
			             < 0x0 0x18f 0x2 0xa0 >,
			             < 0x0 0x18f 0x2 0xa0 >; /* in zephyr/dts/arm64/renesas/rz/rza/r9a07g063.dtsi:532 */
			interrupt-names = "eri",
			                  "bri",
			                  "rxi",
			                  "txi",
			                  "tei";             /* in zephyr/dts/arm64/renesas/rz/rza/r9a07g063.dtsi:537 */
			status = "disabled";                 /* in zephyr/dts/arm64/renesas/rz/rza/r9a07g063.dtsi:538 */
		};

		/* node '/soc/serial@1004c800' defined in zephyr/dts/arm64/renesas/rz/rza/r9a07g063.dtsi:541 */
		scif4: serial@1004c800 {
			compatible = "renesas,rz-scif-uart"; /* in zephyr/dts/arm64/renesas/rz/rza/r9a07g063.dtsi:542 */
			channel = < 0x4 >;                   /* in zephyr/dts/arm64/renesas/rz/rza/r9a07g063.dtsi:543 */
			reg = < 0x1004c800 0x400 >;          /* in zephyr/dts/arm64/renesas/rz/rza/r9a07g063.dtsi:544 */
			interrupts = < 0x0 0x190 0x2 0xa0 >,
			             < 0x0 0x191 0x2 0xa0 >,
			             < 0x0 0x192 0x2 0xa0 >,
			             < 0x0 0x193 0x2 0xa0 >,
			             < 0x0 0x194 0x2 0xa0 >; /* in zephyr/dts/arm64/renesas/rz/rza/r9a07g063.dtsi:545 */
			interrupt-names = "eri",
			                  "bri",
			                  "rxi",
			                  "txi",
			                  "tei";             /* in zephyr/dts/arm64/renesas/rz/rza/r9a07g063.dtsi:550 */
			status = "disabled";                 /* in zephyr/dts/arm64/renesas/rz/rza/r9a07g063.dtsi:551 */
		};

		/* node '/soc/mtu0@10001290' defined in zephyr/dts/arm64/renesas/rz/rza/r9a07g063.dtsi:554 */
		mtu0: mtu0@10001290 {
			compatible = "renesas,rz-mtu";      /* in zephyr/dts/arm64/renesas/rz/rza/r9a07g063.dtsi:555 */
			channel = < 0x0 >;                  /* in zephyr/dts/arm64/renesas/rz/rza/r9a07g063.dtsi:556 */
			reg = < 0x10001290 0x99 >;          /* in zephyr/dts/arm64/renesas/rz/rza/r9a07g063.dtsi:557 */
			interrupts = < 0x0 0xaa 0x4 0xa0 >,
			             < 0x0 0xab 0x4 0xa0 >,
			             < 0x0 0xac 0x4 0xa0 >,
			             < 0x0 0xad 0x4 0xa0 >,
			             < 0x0 0xae 0x4 0xa0 >,
			             < 0x0 0xaf 0x4 0xa0 >,
			             < 0x0 0xb0 0x4 0xa0 >; /* in zephyr/dts/arm64/renesas/rz/rza/r9a07g063.dtsi:558 */
			interrupt-names = "tgia",
			                  "tgib",
			                  "tgic",
			                  "tgid",
			                  "tciv",
			                  "tgie",
			                  "tgif";           /* in zephyr/dts/arm64/renesas/rz/rza/r9a07g063.dtsi:565 */
			prescaler = < 0x1 >;                /* in zephyr/dts/arm64/renesas/rz/rza/r9a07g063.dtsi:566 */
			status = "disabled";                /* in zephyr/dts/arm64/renesas/rz/rza/r9a07g063.dtsi:567 */

			/* node '/soc/mtu0@10001290/pwm' defined in zephyr/dts/arm64/renesas/rz/rza/r9a07g063.dtsi:569 */
			pwm {
				compatible = "renesas,rz-mtu-pwm"; /* in zephyr/dts/arm64/renesas/rz/rza/r9a07g063.dtsi:570 */
				#pwm-cells = < 0x3 >;              /* in zephyr/dts/arm64/renesas/rz/rza/r9a07g063.dtsi:571 */
				status = "disabled";               /* in zephyr/dts/arm64/renesas/rz/rza/r9a07g063.dtsi:572 */
			};
		};

		/* node '/soc/mtu1@10001291' defined in zephyr/dts/arm64/renesas/rz/rza/r9a07g063.dtsi:576 */
		mtu1: mtu1@10001291 {
			compatible = "renesas,rz-mtu";      /* in zephyr/dts/arm64/renesas/rz/rza/r9a07g063.dtsi:577 */
			channel = < 0x1 >;                  /* in zephyr/dts/arm64/renesas/rz/rza/r9a07g063.dtsi:578 */
			reg = < 0x10001291 0x11b >;         /* in zephyr/dts/arm64/renesas/rz/rza/r9a07g063.dtsi:579 */
			interrupts = < 0x0 0xb1 0x4 0xa0 >,
			             < 0x0 0xb2 0x4 0xa0 >,
			             < 0x0 0xb3 0x4 0xa0 >,
			             < 0x0 0xb4 0x4 0xa0 >; /* in zephyr/dts/arm64/renesas/rz/rza/r9a07g063.dtsi:580 */
			interrupt-names = "tgia",
			                  "tgib",
			                  "tciv",
			                  "tciu";           /* in zephyr/dts/arm64/renesas/rz/rza/r9a07g063.dtsi:584 */
			prescaler = < 0x1 >;                /* in zephyr/dts/arm64/renesas/rz/rza/r9a07g063.dtsi:585 */
			status = "disabled";                /* in zephyr/dts/arm64/renesas/rz/rza/r9a07g063.dtsi:586 */

			/* node '/soc/mtu1@10001291/pwm' defined in zephyr/dts/arm64/renesas/rz/rza/r9a07g063.dtsi:588 */
			pwm {
				compatible = "renesas,rz-mtu-pwm"; /* in zephyr/dts/arm64/renesas/rz/rza/r9a07g063.dtsi:589 */
				#pwm-cells = < 0x3 >;              /* in zephyr/dts/arm64/renesas/rz/rza/r9a07g063.dtsi:590 */
				status = "disabled";               /* in zephyr/dts/arm64/renesas/rz/rza/r9a07g063.dtsi:591 */
			};
		};

		/* node '/soc/mtu2@10001292' defined in zephyr/dts/arm64/renesas/rz/rza/r9a07g063.dtsi:595 */
		mtu2: mtu2@10001292 {
			compatible = "renesas,rz-mtu";      /* in zephyr/dts/arm64/renesas/rz/rza/r9a07g063.dtsi:596 */
			channel = < 0x2 >;                  /* in zephyr/dts/arm64/renesas/rz/rza/r9a07g063.dtsi:597 */
			reg = < 0x10001292 0x17b >;         /* in zephyr/dts/arm64/renesas/rz/rza/r9a07g063.dtsi:598 */
			interrupts = < 0x0 0xb5 0x4 0xa0 >,
			             < 0x0 0xb6 0x4 0xa0 >,
			             < 0x0 0xb7 0x4 0xa0 >,
			             < 0x0 0xb8 0x4 0xa0 >; /* in zephyr/dts/arm64/renesas/rz/rza/r9a07g063.dtsi:599 */
			interrupt-names = "tgia",
			                  "tgib",
			                  "tciv",
			                  "tciu";           /* in zephyr/dts/arm64/renesas/rz/rza/r9a07g063.dtsi:603 */
			prescaler = < 0x1 >;                /* in zephyr/dts/arm64/renesas/rz/rza/r9a07g063.dtsi:604 */
			status = "disabled";                /* in zephyr/dts/arm64/renesas/rz/rza/r9a07g063.dtsi:605 */

			/* node '/soc/mtu2@10001292/pwm' defined in zephyr/dts/arm64/renesas/rz/rza/r9a07g063.dtsi:607 */
			pwm {
				compatible = "renesas,rz-mtu-pwm"; /* in zephyr/dts/arm64/renesas/rz/rza/r9a07g063.dtsi:608 */
				#pwm-cells = < 0x3 >;              /* in zephyr/dts/arm64/renesas/rz/rza/r9a07g063.dtsi:609 */
				status = "disabled";               /* in zephyr/dts/arm64/renesas/rz/rza/r9a07g063.dtsi:610 */
			};
		};

		/* node '/soc/mtu3@10001200' defined in zephyr/dts/arm64/renesas/rz/rza/r9a07g063.dtsi:614 */
		mtu3: mtu3@10001200 {
			compatible = "renesas,rz-mtu";      /* in zephyr/dts/arm64/renesas/rz/rza/r9a07g063.dtsi:615 */
			channel = < 0x3 >;                  /* in zephyr/dts/arm64/renesas/rz/rza/r9a07g063.dtsi:616 */
			reg = < 0x10001200 0x94 >;          /* in zephyr/dts/arm64/renesas/rz/rza/r9a07g063.dtsi:617 */
			interrupts = < 0x0 0xb9 0x4 0xa0 >,
			             < 0x0 0xba 0x4 0xa0 >,
			             < 0x0 0xbb 0x4 0xa0 >,
			             < 0x0 0xbc 0x4 0xa0 >,
			             < 0x0 0xbd 0x4 0xa0 >; /* in zephyr/dts/arm64/renesas/rz/rza/r9a07g063.dtsi:618 */
			interrupt-names = "tgia",
			                  "tgib",
			                  "tgic",
			                  "tgid",
			                  "tciv";           /* in zephyr/dts/arm64/renesas/rz/rza/r9a07g063.dtsi:623 */
			prescaler = < 0x1 >;                /* in zephyr/dts/arm64/renesas/rz/rza/r9a07g063.dtsi:624 */
			status = "disabled";                /* in zephyr/dts/arm64/renesas/rz/rza/r9a07g063.dtsi:625 */

			/* node '/soc/mtu3@10001200/pwm' defined in zephyr/dts/arm64/renesas/rz/rza/r9a07g063.dtsi:627 */
			pwm {
				compatible = "renesas,rz-mtu-pwm"; /* in zephyr/dts/arm64/renesas/rz/rza/r9a07g063.dtsi:628 */
				#pwm-cells = < 0x3 >;              /* in zephyr/dts/arm64/renesas/rz/rza/r9a07g063.dtsi:629 */
				status = "disabled";               /* in zephyr/dts/arm64/renesas/rz/rza/r9a07g063.dtsi:630 */
			};
		};

		/* node '/soc/mtu4@10001201' defined in zephyr/dts/arm64/renesas/rz/rza/r9a07g063.dtsi:634 */
		mtu4: mtu4@10001201 {
			compatible = "renesas,rz-mtu";      /* in zephyr/dts/arm64/renesas/rz/rza/r9a07g063.dtsi:635 */
			channel = < 0x4 >;                  /* in zephyr/dts/arm64/renesas/rz/rza/r9a07g063.dtsi:636 */
			reg = < 0x10001201 0x94 >;          /* in zephyr/dts/arm64/renesas/rz/rza/r9a07g063.dtsi:637 */
			interrupts = < 0x0 0xbe 0x4 0xa0 >,
			             < 0x0 0xbf 0x4 0xa0 >,
			             < 0x0 0xc0 0x4 0xa0 >,
			             < 0x0 0xc1 0x4 0xa0 >,
			             < 0x0 0xc2 0x4 0xa0 >; /* in zephyr/dts/arm64/renesas/rz/rza/r9a07g063.dtsi:638 */
			interrupt-names = "tgia",
			                  "tgib",
			                  "tgic",
			                  "tgid",
			                  "tciv";           /* in zephyr/dts/arm64/renesas/rz/rza/r9a07g063.dtsi:643 */
			prescaler = < 0x1 >;                /* in zephyr/dts/arm64/renesas/rz/rza/r9a07g063.dtsi:644 */
			status = "disabled";                /* in zephyr/dts/arm64/renesas/rz/rza/r9a07g063.dtsi:645 */

			/* node '/soc/mtu4@10001201/pwm' defined in zephyr/dts/arm64/renesas/rz/rza/r9a07g063.dtsi:647 */
			pwm {
				compatible = "renesas,rz-mtu-pwm"; /* in zephyr/dts/arm64/renesas/rz/rza/r9a07g063.dtsi:648 */
				#pwm-cells = < 0x3 >;              /* in zephyr/dts/arm64/renesas/rz/rza/r9a07g063.dtsi:649 */
				status = "disabled";               /* in zephyr/dts/arm64/renesas/rz/rza/r9a07g063.dtsi:650 */
			};
		};

		/* node '/soc/mtu6@10001a00' defined in zephyr/dts/arm64/renesas/rz/rza/r9a07g063.dtsi:654 */
		mtu6: mtu6@10001a00 {
			compatible = "renesas,rz-mtu";      /* in zephyr/dts/arm64/renesas/rz/rza/r9a07g063.dtsi:655 */
			channel = < 0x6 >;                  /* in zephyr/dts/arm64/renesas/rz/rza/r9a07g063.dtsi:656 */
			reg = < 0x10001a00 0x94 >;          /* in zephyr/dts/arm64/renesas/rz/rza/r9a07g063.dtsi:657 */
			interrupts = < 0x0 0xc6 0x4 0xa0 >,
			             < 0x0 0xc7 0x4 0xa0 >,
			             < 0x0 0xc8 0x4 0xa0 >,
			             < 0x0 0xc9 0x4 0xa0 >,
			             < 0x0 0xca 0x4 0xa0 >; /* in zephyr/dts/arm64/renesas/rz/rza/r9a07g063.dtsi:658 */
			interrupt-names = "tgia",
			                  "tgib",
			                  "tgic",
			                  "tgid",
			                  "tciv";           /* in zephyr/dts/arm64/renesas/rz/rza/r9a07g063.dtsi:663 */
			prescaler = < 0x1 >;                /* in zephyr/dts/arm64/renesas/rz/rza/r9a07g063.dtsi:664 */
			status = "disabled";                /* in zephyr/dts/arm64/renesas/rz/rza/r9a07g063.dtsi:665 */

			/* node '/soc/mtu6@10001a00/pwm' defined in zephyr/dts/arm64/renesas/rz/rza/r9a07g063.dtsi:667 */
			pwm {
				compatible = "renesas,rz-mtu-pwm"; /* in zephyr/dts/arm64/renesas/rz/rza/r9a07g063.dtsi:668 */
				#pwm-cells = < 0x3 >;              /* in zephyr/dts/arm64/renesas/rz/rza/r9a07g063.dtsi:669 */
				status = "disabled";               /* in zephyr/dts/arm64/renesas/rz/rza/r9a07g063.dtsi:670 */
			};
		};

		/* node '/soc/mtu7@10001a01' defined in zephyr/dts/arm64/renesas/rz/rza/r9a07g063.dtsi:674 */
		mtu7: mtu7@10001a01 {
			compatible = "renesas,rz-mtu";      /* in zephyr/dts/arm64/renesas/rz/rza/r9a07g063.dtsi:675 */
			channel = < 0x7 >;                  /* in zephyr/dts/arm64/renesas/rz/rza/r9a07g063.dtsi:676 */
			reg = < 0x10001a01 0x94 >;          /* in zephyr/dts/arm64/renesas/rz/rza/r9a07g063.dtsi:677 */
			interrupts = < 0x0 0xcb 0x4 0xa0 >,
			             < 0x0 0xcc 0x4 0xa0 >,
			             < 0x0 0xcd 0x4 0xa0 >,
			             < 0x0 0xce 0x4 0xa0 >,
			             < 0x0 0xcf 0x4 0xa0 >; /* in zephyr/dts/arm64/renesas/rz/rza/r9a07g063.dtsi:678 */
			interrupt-names = "tgia",
			                  "tgib",
			                  "tgic",
			                  "tgid",
			                  "tciv";           /* in zephyr/dts/arm64/renesas/rz/rza/r9a07g063.dtsi:683 */
			prescaler = < 0x1 >;                /* in zephyr/dts/arm64/renesas/rz/rza/r9a07g063.dtsi:684 */
			status = "disabled";                /* in zephyr/dts/arm64/renesas/rz/rza/r9a07g063.dtsi:685 */

			/* node '/soc/mtu7@10001a01/pwm' defined in zephyr/dts/arm64/renesas/rz/rza/r9a07g063.dtsi:687 */
			pwm {
				compatible = "renesas,rz-mtu-pwm"; /* in zephyr/dts/arm64/renesas/rz/rza/r9a07g063.dtsi:688 */
				#pwm-cells = < 0x3 >;              /* in zephyr/dts/arm64/renesas/rz/rza/r9a07g063.dtsi:689 */
				status = "disabled";               /* in zephyr/dts/arm64/renesas/rz/rza/r9a07g063.dtsi:690 */
			};
		};

		/* node '/soc/intc@110a0000' defined in zephyr/dts/arm64/renesas/rz/rza/r9a07g063.dtsi:694 */
		intc: intc@110a0000 {
			compatible = "renesas,rz-intc"; /* in zephyr/dts/arm64/renesas/rz/rza/r9a07g063.dtsi:695 */
			reg = < 0x110a0000 0x10000 >;   /* in zephyr/dts/arm64/renesas/rz/rza/r9a07g063.dtsi:696 */
			#address-cells = < 0x1 >;       /* in zephyr/dts/arm64/renesas/rz/rza/r9a07g063.dtsi:697 */
			#size-cells = < 0x0 >;          /* in zephyr/dts/arm64/renesas/rz/rza/r9a07g063.dtsi:698 */
			interrupt-parent = < &gic >;    /* in zephyr/dts/arm64/renesas/rz/rza/r9a07g063.dtsi:699 */

			/* node '/soc/intc@110a0000/nmi' defined in zephyr/dts/arm64/renesas/rz/rza/r9a07g063.dtsi:701 */
			nmi: nmi {
				compatible = "renesas,rz-ext-irq"; /* in zephyr/dts/arm64/renesas/rz/rza/r9a07g063.dtsi:702 */
				interrupt-controller;              /* in zephyr/dts/arm64/renesas/rz/rza/r9a07g063.dtsi:703 */
				#interrupt-cells = < 0x2 >;        /* in zephyr/dts/arm64/renesas/rz/rza/r9a07g063.dtsi:704 */
				interrupts = < 0x0 0x0 0x2 0xa0 >; /* in zephyr/dts/arm64/renesas/rz/rza/r9a07g063.dtsi:705 */
				status = "disabled";               /* in zephyr/dts/arm64/renesas/rz/rza/r9a07g063.dtsi:706 */
			};

			/* node '/soc/intc@110a0000/irq@0' defined in zephyr/dts/arm64/renesas/rz/rza/r9a07g063.dtsi:709 */
			irq0: irq@0 {
				compatible = "renesas,rz-ext-irq"; /* in zephyr/dts/arm64/renesas/rz/rza/r9a07g063.dtsi:710 */
				reg = < 0x0 >;                     /* in zephyr/dts/arm64/renesas/rz/rza/r9a07g063.dtsi:711 */
				interrupt-controller;              /* in zephyr/dts/arm64/renesas/rz/rza/r9a07g063.dtsi:712 */
				#interrupt-cells = < 0x2 >;        /* in zephyr/dts/arm64/renesas/rz/rza/r9a07g063.dtsi:713 */
				interrupts = < 0x0 0x1 0x2 0xa0 >; /* in zephyr/dts/arm64/renesas/rz/rza/r9a07g063.dtsi:714 */
				status = "disabled";               /* in zephyr/dts/arm64/renesas/rz/rza/r9a07g063.dtsi:715 */
			};

			/* node '/soc/intc@110a0000/irq@1' defined in zephyr/dts/arm64/renesas/rz/rza/r9a07g063.dtsi:718 */
			irq1: irq@1 {
				compatible = "renesas,rz-ext-irq"; /* in zephyr/dts/arm64/renesas/rz/rza/r9a07g063.dtsi:719 */
				reg = < 0x1 >;                     /* in zephyr/dts/arm64/renesas/rz/rza/r9a07g063.dtsi:720 */
				interrupt-controller;              /* in zephyr/dts/arm64/renesas/rz/rza/r9a07g063.dtsi:721 */
				#interrupt-cells = < 0x2 >;        /* in zephyr/dts/arm64/renesas/rz/rza/r9a07g063.dtsi:722 */
				interrupts = < 0x0 0x2 0x2 0xa0 >; /* in zephyr/dts/arm64/renesas/rz/rza/r9a07g063.dtsi:723 */
				status = "disabled";               /* in zephyr/dts/arm64/renesas/rz/rza/r9a07g063.dtsi:724 */
			};

			/* node '/soc/intc@110a0000/irq@2' defined in zephyr/dts/arm64/renesas/rz/rza/r9a07g063.dtsi:727 */
			irq2: irq@2 {
				compatible = "renesas,rz-ext-irq"; /* in zephyr/dts/arm64/renesas/rz/rza/r9a07g063.dtsi:728 */
				reg = < 0x2 >;                     /* in zephyr/dts/arm64/renesas/rz/rza/r9a07g063.dtsi:729 */
				interrupt-controller;              /* in zephyr/dts/arm64/renesas/rz/rza/r9a07g063.dtsi:730 */
				#interrupt-cells = < 0x2 >;        /* in zephyr/dts/arm64/renesas/rz/rza/r9a07g063.dtsi:731 */
				interrupts = < 0x0 0x3 0x2 0xa0 >; /* in zephyr/dts/arm64/renesas/rz/rza/r9a07g063.dtsi:732 */
				status = "disabled";               /* in zephyr/dts/arm64/renesas/rz/rza/r9a07g063.dtsi:733 */
			};

			/* node '/soc/intc@110a0000/irq@3' defined in zephyr/dts/arm64/renesas/rz/rza/r9a07g063.dtsi:736 */
			irq3: irq@3 {
				compatible = "renesas,rz-ext-irq"; /* in zephyr/dts/arm64/renesas/rz/rza/r9a07g063.dtsi:737 */
				reg = < 0x3 >;                     /* in zephyr/dts/arm64/renesas/rz/rza/r9a07g063.dtsi:738 */
				interrupt-controller;              /* in zephyr/dts/arm64/renesas/rz/rza/r9a07g063.dtsi:739 */
				#interrupt-cells = < 0x2 >;        /* in zephyr/dts/arm64/renesas/rz/rza/r9a07g063.dtsi:740 */
				interrupts = < 0x0 0x4 0x2 0xa0 >; /* in zephyr/dts/arm64/renesas/rz/rza/r9a07g063.dtsi:741 */
				status = "disabled";               /* in zephyr/dts/arm64/renesas/rz/rza/r9a07g063.dtsi:742 */
			};

			/* node '/soc/intc@110a0000/irq@4' defined in zephyr/dts/arm64/renesas/rz/rza/r9a07g063.dtsi:745 */
			irq4: irq@4 {
				compatible = "renesas,rz-ext-irq"; /* in zephyr/dts/arm64/renesas/rz/rza/r9a07g063.dtsi:746 */
				reg = < 0x4 >;                     /* in zephyr/dts/arm64/renesas/rz/rza/r9a07g063.dtsi:747 */
				interrupt-controller;              /* in zephyr/dts/arm64/renesas/rz/rza/r9a07g063.dtsi:748 */
				#interrupt-cells = < 0x2 >;        /* in zephyr/dts/arm64/renesas/rz/rza/r9a07g063.dtsi:749 */
				interrupts = < 0x0 0x5 0x2 0xa0 >; /* in zephyr/dts/arm64/renesas/rz/rza/r9a07g063.dtsi:750 */
				status = "disabled";               /* in zephyr/dts/arm64/renesas/rz/rza/r9a07g063.dtsi:751 */
			};

			/* node '/soc/intc@110a0000/irq@5' defined in zephyr/dts/arm64/renesas/rz/rza/r9a07g063.dtsi:754 */
			irq5: irq@5 {
				compatible = "renesas,rz-ext-irq"; /* in zephyr/dts/arm64/renesas/rz/rza/r9a07g063.dtsi:755 */
				reg = < 0x5 >;                     /* in zephyr/dts/arm64/renesas/rz/rza/r9a07g063.dtsi:756 */
				interrupt-controller;              /* in zephyr/dts/arm64/renesas/rz/rza/r9a07g063.dtsi:757 */
				#interrupt-cells = < 0x2 >;        /* in zephyr/dts/arm64/renesas/rz/rza/r9a07g063.dtsi:758 */
				interrupts = < 0x0 0x6 0x2 0xa0 >; /* in zephyr/dts/arm64/renesas/rz/rza/r9a07g063.dtsi:759 */
				status = "disabled";               /* in zephyr/dts/arm64/renesas/rz/rza/r9a07g063.dtsi:760 */
			};

			/* node '/soc/intc@110a0000/irq@6' defined in zephyr/dts/arm64/renesas/rz/rza/r9a07g063.dtsi:763 */
			irq6: irq@6 {
				compatible = "renesas,rz-ext-irq"; /* in zephyr/dts/arm64/renesas/rz/rza/r9a07g063.dtsi:764 */
				reg = < 0x6 >;                     /* in zephyr/dts/arm64/renesas/rz/rza/r9a07g063.dtsi:765 */
				interrupt-controller;              /* in zephyr/dts/arm64/renesas/rz/rza/r9a07g063.dtsi:766 */
				#interrupt-cells = < 0x2 >;        /* in zephyr/dts/arm64/renesas/rz/rza/r9a07g063.dtsi:767 */
				interrupts = < 0x0 0x7 0x2 0xa0 >; /* in zephyr/dts/arm64/renesas/rz/rza/r9a07g063.dtsi:768 */
				status = "disabled";               /* in zephyr/dts/arm64/renesas/rz/rza/r9a07g063.dtsi:769 */
			};

			/* node '/soc/intc@110a0000/irq@7' defined in zephyr/dts/arm64/renesas/rz/rza/r9a07g063.dtsi:772 */
			irq7: irq@7 {
				compatible = "renesas,rz-ext-irq"; /* in zephyr/dts/arm64/renesas/rz/rza/r9a07g063.dtsi:773 */
				reg = < 0x7 >;                     /* in zephyr/dts/arm64/renesas/rz/rza/r9a07g063.dtsi:774 */
				interrupt-controller;              /* in zephyr/dts/arm64/renesas/rz/rza/r9a07g063.dtsi:775 */
				#interrupt-cells = < 0x2 >;        /* in zephyr/dts/arm64/renesas/rz/rza/r9a07g063.dtsi:776 */
				interrupts = < 0x0 0x8 0x2 0xa0 >; /* in zephyr/dts/arm64/renesas/rz/rza/r9a07g063.dtsi:777 */
				status = "disabled";               /* in zephyr/dts/arm64/renesas/rz/rza/r9a07g063.dtsi:778 */
			};
		};

		/* node '/soc/i2c@10058000' defined in zephyr/dts/arm64/renesas/rz/rza/r9a07g063.dtsi:782 */
		i2c0: i2c@10058000 {
			compatible = "renesas,rz-riic";      /* in zephyr/dts/arm64/renesas/rz/rza/r9a07g063.dtsi:783 */
			channel = < 0x0 >;                   /* in zephyr/dts/arm64/renesas/rz/rza/r9a07g063.dtsi:784 */
			clock-frequency = < 0x186a0 >;       /* in zephyr/dts/arm64/renesas/rz/rza/r9a07g063.dtsi:785 */
			#address-cells = < 0x1 >;            /* in zephyr/dts/arm64/renesas/rz/rza/r9a07g063.dtsi:786 */
			#size-cells = < 0x0 >;               /* in zephyr/dts/arm64/renesas/rz/rza/r9a07g063.dtsi:787 */
			reg = < 0x10058000 0x400 >;          /* in zephyr/dts/arm64/renesas/rz/rza/r9a07g063.dtsi:788 */
			interrupts = < 0x0 0x15c 0x4 0xa0 >,
			             < 0x0 0x15d 0x4 0xa0 >,
			             < 0x0 0x15e 0x2 0xa0 >,
			             < 0x0 0x15f 0x2 0xa0 >,
			             < 0x0 0x160 0x2 0xa0 >,
			             < 0x0 0x161 0x2 0xa0 >,
			             < 0x0 0x162 0x2 0xa0 >,
			             < 0x0 0x163 0x2 0xa0 >; /* in zephyr/dts/arm64/renesas/rz/rza/r9a07g063.dtsi:789 */
			interrupt-names = "rxi",
			                  "txi",
			                  "tei",
			                  "naki",
			                  "spi",
			                  "sti",
			                  "ali",
			                  "tmoi";            /* in zephyr/dts/arm64/renesas/rz/rza/r9a07g063.dtsi:797 */
			status = "disabled";                 /* in zephyr/dts/arm64/renesas/rz/rza/r9a07g063.dtsi:798 */
		};

		/* node '/soc/i2c@10058400' defined in zephyr/dts/arm64/renesas/rz/rza/r9a07g063.dtsi:801 */
		i2c1: i2c@10058400 {
			compatible = "renesas,rz-riic";      /* in zephyr/dts/arm64/renesas/rz/rza/r9a07g063.dtsi:802 */
			channel = < 0x1 >;                   /* in zephyr/dts/arm64/renesas/rz/rza/r9a07g063.dtsi:803 */
			clock-frequency = < 0x186a0 >;       /* in zephyr/dts/arm64/renesas/rz/rza/r9a07g063.dtsi:804 */
			#address-cells = < 0x1 >;            /* in zephyr/dts/arm64/renesas/rz/rza/r9a07g063.dtsi:805 */
			#size-cells = < 0x0 >;               /* in zephyr/dts/arm64/renesas/rz/rza/r9a07g063.dtsi:806 */
			reg = < 0x10058400 0x400 >;          /* in zephyr/dts/arm64/renesas/rz/rza/r9a07g063.dtsi:807 */
			interrupts = < 0x0 0x164 0x4 0xa0 >,
			             < 0x0 0x165 0x4 0xa0 >,
			             < 0x0 0x166 0x2 0xa0 >,
			             < 0x0 0x167 0x2 0xa0 >,
			             < 0x0 0x168 0x2 0xa0 >,
			             < 0x0 0x169 0x2 0xa0 >,
			             < 0x0 0x16a 0x2 0xa0 >,
			             < 0x0 0x16b 0x2 0xa0 >; /* in zephyr/dts/arm64/renesas/rz/rza/r9a07g063.dtsi:808 */
			interrupt-names = "rxi",
			                  "txi",
			                  "tei",
			                  "naki",
			                  "spi",
			                  "sti",
			                  "ali",
			                  "tmoi";            /* in zephyr/dts/arm64/renesas/rz/rza/r9a07g063.dtsi:816 */
			pinctrl-0 = < &i2c1_pins >;          /* in zephyr/boards/renesas/rza3ul_smarc/rza3ul_smarc.dts:57 */
			pinctrl-names = "default";           /* in zephyr/boards/renesas/rza3ul_smarc/rza3ul_smarc.dts:58 */
			status = "okay";                     /* in zephyr/boards/renesas/rza3ul_smarc/rza3ul_smarc.dts:59 */
		};

		/* node '/soc/i2c@10058800' defined in zephyr/dts/arm64/renesas/rz/rza/r9a07g063.dtsi:820 */
		i2c2: i2c@10058800 {
			compatible = "renesas,rz-riic";      /* in zephyr/dts/arm64/renesas/rz/rza/r9a07g063.dtsi:821 */
			channel = < 0x2 >;                   /* in zephyr/dts/arm64/renesas/rz/rza/r9a07g063.dtsi:822 */
			clock-frequency = < 0x186a0 >;       /* in zephyr/dts/arm64/renesas/rz/rza/r9a07g063.dtsi:823 */
			#address-cells = < 0x1 >;            /* in zephyr/dts/arm64/renesas/rz/rza/r9a07g063.dtsi:824 */
			#size-cells = < 0x0 >;               /* in zephyr/dts/arm64/renesas/rz/rza/r9a07g063.dtsi:825 */
			reg = < 0x10058800 0x400 >;          /* in zephyr/dts/arm64/renesas/rz/rza/r9a07g063.dtsi:826 */
			interrupts = < 0x0 0x16c 0x4 0xa0 >,
			             < 0x0 0x16d 0x4 0xa0 >,
			             < 0x0 0x16e 0x2 0xa0 >,
			             < 0x0 0x16f 0x2 0xa0 >,
			             < 0x0 0x170 0x2 0xa0 >,
			             < 0x0 0x171 0x2 0xa0 >,
			             < 0x0 0x172 0x2 0xa0 >,
			             < 0x0 0x173 0x2 0xa0 >; /* in zephyr/dts/arm64/renesas/rz/rza/r9a07g063.dtsi:827 */
			interrupt-names = "rxi",
			                  "txi",
			                  "tei",
			                  "naki",
			                  "spi",
			                  "sti",
			                  "ali",
			                  "tmoi";            /* in zephyr/dts/arm64/renesas/rz/rza/r9a07g063.dtsi:835 */
			status = "disabled";                 /* in zephyr/dts/arm64/renesas/rz/rza/r9a07g063.dtsi:836 */
		};

		/* node '/soc/i2c@10058c00' defined in zephyr/dts/arm64/renesas/rz/rza/r9a07g063.dtsi:839 */
		i2c3: i2c@10058c00 {
			compatible = "renesas,rz-riic";      /* in zephyr/dts/arm64/renesas/rz/rza/r9a07g063.dtsi:840 */
			channel = < 0x3 >;                   /* in zephyr/dts/arm64/renesas/rz/rza/r9a07g063.dtsi:841 */
			clock-frequency = < 0x186a0 >;       /* in zephyr/dts/arm64/renesas/rz/rza/r9a07g063.dtsi:842 */
			#address-cells = < 0x1 >;            /* in zephyr/dts/arm64/renesas/rz/rza/r9a07g063.dtsi:843 */
			#size-cells = < 0x0 >;               /* in zephyr/dts/arm64/renesas/rz/rza/r9a07g063.dtsi:844 */
			reg = < 0x10058c00 0x400 >;          /* in zephyr/dts/arm64/renesas/rz/rza/r9a07g063.dtsi:845 */
			interrupts = < 0x0 0x174 0x4 0xa0 >,
			             < 0x0 0x175 0x4 0xa0 >,
			             < 0x0 0x176 0x2 0xa0 >,
			             < 0x0 0x177 0x2 0xa0 >,
			             < 0x0 0x178 0x2 0xa0 >,
			             < 0x0 0x179 0x2 0xa0 >,
			             < 0x0 0x17a 0x2 0xa0 >,
			             < 0x0 0x17b 0x2 0xa0 >; /* in zephyr/dts/arm64/renesas/rz/rza/r9a07g063.dtsi:846 */
			interrupt-names = "rxi",
			                  "txi",
			                  "tei",
			                  "naki",
			                  "spi",
			                  "sti",
			                  "ali",
			                  "tmoi";            /* in zephyr/dts/arm64/renesas/rz/rza/r9a07g063.dtsi:854 */
			status = "disabled";                 /* in zephyr/dts/arm64/renesas/rz/rza/r9a07g063.dtsi:855 */
		};

		/* node '/soc/spi@1004ac00' defined in zephyr/dts/arm64/renesas/rz/rza/r9a07g063.dtsi:858 */
		spi0: spi@1004ac00 {
			compatible = "renesas,rz-rspi";      /* in zephyr/dts/arm64/renesas/rz/rza/r9a07g063.dtsi:859 */
			reg = < 0x1004ac00 0x400 >;          /* in zephyr/dts/arm64/renesas/rz/rza/r9a07g063.dtsi:860 */
			interrupts = < 0x0 0x19d 0x2 0xa0 >,
			             < 0x0 0x19e 0x2 0xa0 >,
			             < 0x0 0x19f 0x2 0xa0 >; /* in zephyr/dts/arm64/renesas/rz/rza/r9a07g063.dtsi:861 */
			interrupt-names = "rx",
			                  "tx",
			                  "error";           /* in zephyr/dts/arm64/renesas/rz/rza/r9a07g063.dtsi:864 */
			channel = < 0x0 >;                   /* in zephyr/dts/arm64/renesas/rz/rza/r9a07g063.dtsi:865 */
			#address-cells = < 0x1 >;            /* in zephyr/dts/arm64/renesas/rz/rza/r9a07g063.dtsi:866 */
			#size-cells = < 0x0 >;               /* in zephyr/dts/arm64/renesas/rz/rza/r9a07g063.dtsi:867 */
			pinctrl-0 = < &spi0_pins >;          /* in zephyr/boards/renesas/rza3ul_smarc/rza3ul_smarc.dts:63 */
			pinctrl-names = "default";           /* in zephyr/boards/renesas/rza3ul_smarc/rza3ul_smarc.dts:64 */
			status = "okay";                     /* in zephyr/boards/renesas/rza3ul_smarc/rza3ul_smarc.dts:65 */
		};

		/* node '/soc/spi@1004b000' defined in zephyr/dts/arm64/renesas/rz/rza/r9a07g063.dtsi:871 */
		spi1: spi@1004b000 {
			compatible = "renesas,rz-rspi";      /* in zephyr/dts/arm64/renesas/rz/rza/r9a07g063.dtsi:872 */
			reg = < 0x1004b000 0x400 >;          /* in zephyr/dts/arm64/renesas/rz/rza/r9a07g063.dtsi:873 */
			interrupts = < 0x0 0x1a0 0x2 0xa0 >,
			             < 0x0 0x1a1 0x2 0xa0 >,
			             < 0x0 0x1a2 0x2 0xa0 >; /* in zephyr/dts/arm64/renesas/rz/rza/r9a07g063.dtsi:874 */
			interrupt-names = "rx",
			                  "tx",
			                  "error";           /* in zephyr/dts/arm64/renesas/rz/rza/r9a07g063.dtsi:877 */
			channel = < 0x1 >;                   /* in zephyr/dts/arm64/renesas/rz/rza/r9a07g063.dtsi:878 */
			#address-cells = < 0x1 >;            /* in zephyr/dts/arm64/renesas/rz/rza/r9a07g063.dtsi:879 */
			#size-cells = < 0x0 >;               /* in zephyr/dts/arm64/renesas/rz/rza/r9a07g063.dtsi:880 */
			status = "disabled";                 /* in zephyr/dts/arm64/renesas/rz/rza/r9a07g063.dtsi:881 */
		};

		/* node '/soc/spi@1004b400' defined in zephyr/dts/arm64/renesas/rz/rza/r9a07g063.dtsi:884 */
		spi2: spi@1004b400 {
			compatible = "renesas,rz-rspi";      /* in zephyr/dts/arm64/renesas/rz/rza/r9a07g063.dtsi:885 */
			reg = < 0x1004b400 0x400 >;          /* in zephyr/dts/arm64/renesas/rz/rza/r9a07g063.dtsi:886 */
			interrupts = < 0x0 0x1a3 0x2 0xa0 >,
			             < 0x0 0x1a4 0x2 0xa0 >,
			             < 0x0 0x1a5 0x2 0xa0 >; /* in zephyr/dts/arm64/renesas/rz/rza/r9a07g063.dtsi:887 */
			interrupt-names = "rx",
			                  "tx",
			                  "error";           /* in zephyr/dts/arm64/renesas/rz/rza/r9a07g063.dtsi:890 */
			channel = < 0x2 >;                   /* in zephyr/dts/arm64/renesas/rz/rza/r9a07g063.dtsi:891 */
			#address-cells = < 0x1 >;            /* in zephyr/dts/arm64/renesas/rz/rza/r9a07g063.dtsi:892 */
			#size-cells = < 0x0 >;               /* in zephyr/dts/arm64/renesas/rz/rza/r9a07g063.dtsi:893 */
		};

		/* node '/soc/gtm@12801000' defined in zephyr/dts/arm64/renesas/rz/rza/r9a07g063.dtsi:896 */
		gtm0: gtm@12801000 {
			compatible = "renesas,rz-gtm";      /* in zephyr/dts/arm64/renesas/rz/rza/r9a07g063.dtsi:897 */
			reg = < 0x12801000 0x400 >;         /* in zephyr/dts/arm64/renesas/rz/rza/r9a07g063.dtsi:898 */
			channel = < 0x0 >;                  /* in zephyr/dts/arm64/renesas/rz/rza/r9a07g063.dtsi:899 */
			interrupts = < 0x0 0x2e 0x4 0xa0 >; /* in zephyr/dts/arm64/renesas/rz/rza/r9a07g063.dtsi:900 */
			interrupt-names = "overflow";       /* in zephyr/dts/arm64/renesas/rz/rza/r9a07g063.dtsi:901 */
			status = "disabled";                /* in zephyr/dts/arm64/renesas/rz/rza/r9a07g063.dtsi:902 */

			/* node '/soc/gtm@12801000/os_timer' defined in zephyr/dts/arm64/renesas/rz/rza/r9a07g063.dtsi:904 */
			os_timer {
				compatible = "renesas,rz-gtm-os-timer"; /* in zephyr/dts/arm64/renesas/rz/rza/r9a07g063.dtsi:905 */
				status = "disabled";                    /* in zephyr/dts/arm64/renesas/rz/rza/r9a07g063.dtsi:906 */
			};

			/* node '/soc/gtm@12801000/counter' defined in zephyr/dts/arm64/renesas/rz/rza/r9a07g063.dtsi:909 */
			counter {
				compatible = "renesas,rz-gtm-counter"; /* in zephyr/dts/arm64/renesas/rz/rza/r9a07g063.dtsi:910 */
				status = "disabled";                   /* in zephyr/dts/arm64/renesas/rz/rza/r9a07g063.dtsi:911 */
			};
		};

		/* node '/soc/gtm@12801400' defined in zephyr/dts/arm64/renesas/rz/rza/r9a07g063.dtsi:915 */
		gtm1: gtm@12801400 {
			compatible = "renesas,rz-gtm";      /* in zephyr/dts/arm64/renesas/rz/rza/r9a07g063.dtsi:916 */
			reg = < 0x12801400 0x400 >;         /* in zephyr/dts/arm64/renesas/rz/rza/r9a07g063.dtsi:917 */
			channel = < 0x1 >;                  /* in zephyr/dts/arm64/renesas/rz/rza/r9a07g063.dtsi:918 */
			interrupts = < 0x0 0x2f 0x4 0xa0 >; /* in zephyr/dts/arm64/renesas/rz/rza/r9a07g063.dtsi:919 */
			interrupt-names = "overflow";       /* in zephyr/dts/arm64/renesas/rz/rza/r9a07g063.dtsi:920 */
			status = "disabled";                /* in zephyr/dts/arm64/renesas/rz/rza/r9a07g063.dtsi:921 */

			/* node '/soc/gtm@12801400/os_timer' defined in zephyr/dts/arm64/renesas/rz/rza/r9a07g063.dtsi:923 */
			os_timer {
				compatible = "renesas,rz-gtm-os-timer"; /* in zephyr/dts/arm64/renesas/rz/rza/r9a07g063.dtsi:924 */
				status = "disabled";                    /* in zephyr/dts/arm64/renesas/rz/rza/r9a07g063.dtsi:925 */
			};

			/* node '/soc/gtm@12801400/counter' defined in zephyr/dts/arm64/renesas/rz/rza/r9a07g063.dtsi:928 */
			counter {
				compatible = "renesas,rz-gtm-counter"; /* in zephyr/dts/arm64/renesas/rz/rza/r9a07g063.dtsi:929 */
				status = "disabled";                   /* in zephyr/dts/arm64/renesas/rz/rza/r9a07g063.dtsi:930 */
			};
		};

		/* node '/soc/gtm@12801800' defined in zephyr/dts/arm64/renesas/rz/rza/r9a07g063.dtsi:934 */
		gtm2: gtm@12801800 {
			compatible = "renesas,rz-gtm";      /* in zephyr/dts/arm64/renesas/rz/rza/r9a07g063.dtsi:935 */
			reg = < 0x12801800 0x400 >;         /* in zephyr/dts/arm64/renesas/rz/rza/r9a07g063.dtsi:936 */
			channel = < 0x2 >;                  /* in zephyr/dts/arm64/renesas/rz/rza/r9a07g063.dtsi:937 */
			interrupts = < 0x0 0x30 0x4 0xa0 >; /* in zephyr/dts/arm64/renesas/rz/rza/r9a07g063.dtsi:938 */
			interrupt-names = "overflow";       /* in zephyr/dts/arm64/renesas/rz/rza/r9a07g063.dtsi:939 */
			status = "disabled";                /* in zephyr/dts/arm64/renesas/rz/rza/r9a07g063.dtsi:940 */

			/* node '/soc/gtm@12801800/os_timer' defined in zephyr/dts/arm64/renesas/rz/rza/r9a07g063.dtsi:942 */
			os_timer {
				compatible = "renesas,rz-gtm-os-timer"; /* in zephyr/dts/arm64/renesas/rz/rza/r9a07g063.dtsi:943 */
				status = "disabled";                    /* in zephyr/dts/arm64/renesas/rz/rza/r9a07g063.dtsi:944 */
			};

			/* node '/soc/gtm@12801800/counter' defined in zephyr/dts/arm64/renesas/rz/rza/r9a07g063.dtsi:947 */
			counter {
				compatible = "renesas,rz-gtm-counter"; /* in zephyr/dts/arm64/renesas/rz/rza/r9a07g063.dtsi:948 */
				status = "disabled";                   /* in zephyr/dts/arm64/renesas/rz/rza/r9a07g063.dtsi:949 */
			};
		};

		/* node '/soc/dma@11820000' defined in zephyr/dts/arm64/renesas/rz/rza/r9a07g063.dtsi:953 */
		dma0: dma@11820000 {
			compatible = "renesas,rz-dmac";     /* in zephyr/dts/arm64/renesas/rz/rza/r9a07g063.dtsi:954 */
			reg = < 0x11820000 0x800 >,
			      < 0x11830000 0x20 >;          /* in zephyr/dts/arm64/renesas/rz/rza/r9a07g063.dtsi:955 */
			reg-names = "reg_main",
			            "ext";                  /* in zephyr/dts/arm64/renesas/rz/rza/r9a07g063.dtsi:956 */
			interrupts = < 0x0 0x7d 0x4 0xa0 >,
			             < 0x0 0x7e 0x4 0xa0 >,
			             < 0x0 0x7f 0x4 0xa0 >,
			             < 0x0 0x80 0x4 0xa0 >,
			             < 0x0 0x81 0x4 0xa0 >,
			             < 0x0 0x82 0x4 0xa0 >,
			             < 0x0 0x83 0x4 0xa0 >,
			             < 0x0 0x84 0x4 0xa0 >,
			             < 0x0 0x85 0x4 0xa0 >,
			             < 0x0 0x86 0x4 0xa0 >,
			             < 0x0 0x87 0x4 0xa0 >,
			             < 0x0 0x88 0x4 0xa0 >,
			             < 0x0 0x89 0x4 0xa0 >,
			             < 0x0 0x8a 0x4 0xa0 >,
			             < 0x0 0x8b 0x4 0xa0 >,
			             < 0x0 0x8c 0x4 0xa0 >,
			             < 0x0 0x8d 0x4 0xa0 >; /* in zephyr/dts/arm64/renesas/rz/rza/r9a07g063.dtsi:957 */
			interrupt-names = "ch0",
			                  "ch1",
			                  "ch2",
			                  "ch3",
			                  "ch4",
			                  "ch5",
			                  "ch6",
			                  "ch7",
			                  "ch8",
			                  "ch9",
			                  "ch10",
			                  "ch11",
			                  "ch12",
			                  "ch13",
			                  "ch14",
			                  "ch15",
			                  "err1";           /* in zephyr/dts/arm64/renesas/rz/rza/r9a07g063.dtsi:974 */
			dma-channels = < 0x10 >;            /* in zephyr/dts/arm64/renesas/rz/rza/r9a07g063.dtsi:979 */
			#dma-cells = < 0x2 >;               /* in zephyr/dts/arm64/renesas/rz/rza/r9a07g063.dtsi:980 */
			status = "disabled";                /* in zephyr/dts/arm64/renesas/rz/rza/r9a07g063.dtsi:981 */
		};

		/* node '/soc/watchdog@12800800' defined in zephyr/dts/arm64/renesas/rz/rza/r9a07g063.dtsi:984 */
		wdt0: watchdog@12800800 {
			compatible = "renesas,rz-wdt";      /* in zephyr/dts/arm64/renesas/rz/rza/r9a07g063.dtsi:985 */
			reg = < 0x12800800 0x400 >;         /* in zephyr/dts/arm64/renesas/rz/rza/r9a07g063.dtsi:986 */
			interrupts = < 0x0 0x31 0x2 0xa0 >; /* in zephyr/dts/arm64/renesas/rz/rza/r9a07g063.dtsi:987 */
			clock-freq = < 0x16e3600 >;         /* in zephyr/dts/arm64/renesas/rz/rza/r9a07g063.dtsi:988 */
			status = "okay";                    /* in zephyr/boards/renesas/rza3ul_smarc/rza3ul_smarc.dts:69 */
		};

		/* node '/soc/spibsc@10060000' defined in zephyr/dts/arm64/renesas/rz/rza/r9a07g063.dtsi:992 */
		spibsc: spibsc@10060000 {
			compatible = "renesas,rz-spibsc"; /* in zephyr/dts/arm64/renesas/rz/rza/r9a07g063.dtsi:993 */
			reg = < 0x10060000 0x1000 >;      /* in zephyr/dts/arm64/renesas/rz/rza/r9a07g063.dtsi:994 */
			#address-cells = < 0x1 >;         /* in zephyr/dts/arm64/renesas/rz/rza/r9a07g063.dtsi:995 */
			#size-cells = < 0x1 >;            /* in zephyr/dts/arm64/renesas/rz/rza/r9a07g063.dtsi:996 */
			status = "okay";                  /* in zephyr/boards/renesas/rza3ul_smarc/rza3ul_smarc.dts:73 */

			/* node '/soc/spibsc@10060000/qspi-nor-flash@20000000' defined in zephyr/boards/renesas/rza3ul_smarc/rza3ul_smarc.dts:75 */
			at25ql128a: qspi-nor-flash@20000000 {
				compatible = "renesas,rz-qspi-spibsc"; /* in zephyr/boards/renesas/rza3ul_smarc/rza3ul_smarc.dts:76 */
				reg = < 0x20000000 0x1000000 >;        /* in zephyr/boards/renesas/rza3ul_smarc/rza3ul_smarc.dts:77 */
				write-block-size = < 0x1 >;            /* in zephyr/boards/renesas/rza3ul_smarc/rza3ul_smarc.dts:78 */
				erase-block-size = < 0x1000 >;         /* in zephyr/boards/renesas/rza3ul_smarc/rza3ul_smarc.dts:79 */
				status = "okay";                       /* in zephyr/boards/renesas/rza3ul_smarc/rza3ul_smarc.dts:80 */

				/* node '/soc/spibsc@10060000/qspi-nor-flash@20000000/partitions' defined in zephyr/boards/renesas/rza3ul_smarc/rza3ul_smarc.dts:82 */
				partitions {
					compatible = "fixed-partitions"; /* in zephyr/boards/renesas/rza3ul_smarc/rza3ul_smarc.dts:83 */
					#address-cells = < 0x1 >;        /* in zephyr/boards/renesas/rza3ul_smarc/rza3ul_smarc.dts:84 */
					#size-cells = < 0x1 >;           /* in zephyr/boards/renesas/rza3ul_smarc/rza3ul_smarc.dts:85 */

					/* node '/soc/spibsc@10060000/qspi-nor-flash@20000000/partitions/partition@0' defined in zephyr/boards/renesas/rza3ul_smarc/rza3ul_smarc.dts:87 */
					reserved: partition@0 {
						reg = < 0x0 0x20000 >; /* in zephyr/boards/renesas/rza3ul_smarc/rza3ul_smarc.dts:88 */
						read-only;             /* in zephyr/boards/renesas/rza3ul_smarc/rza3ul_smarc.dts:89 */
					};

					/* node '/soc/spibsc@10060000/qspi-nor-flash@20000000/partitions/partition@20000' defined in zephyr/boards/renesas/rza3ul_smarc/rza3ul_smarc.dts:92 */
					header: partition@20000 {
						label = "header";        /* in zephyr/boards/renesas/rza3ul_smarc/rza3ul_smarc.dts:93 */
						reg = < 0x20000 0x200 >; /* in zephyr/boards/renesas/rza3ul_smarc/rza3ul_smarc.dts:94 */
						read-only;               /* in zephyr/boards/renesas/rza3ul_smarc/rza3ul_smarc.dts:95 */
					};

					/* node '/soc/spibsc@10060000/qspi-nor-flash@20000000/partitions/partition@20200' defined in zephyr/boards/renesas/rza3ul_smarc/rza3ul_smarc.dts:98 */
					slot0_partition: partition@20200 {
						label = "image-0";          /* in zephyr/boards/renesas/rza3ul_smarc/rza3ul_smarc.dts:99 */
						reg = < 0x20200 0xfdfe00 >; /* in zephyr/boards/renesas/rza3ul_smarc/rza3ul_smarc.dts:100 */
						read-only;                  /* in zephyr/boards/renesas/rza3ul_smarc/rza3ul_smarc.dts:101 */
					};
				};
			};
		};
	};

	/* node '/cpus' defined in zephyr/dts/arm64/renesas/rz/rza/r9a07g063.dtsi:22 */
	cpus {
		#address-cells = < 0x1 >; /* in zephyr/dts/arm64/renesas/rz/rza/r9a07g063.dtsi:23 */
		#size-cells = < 0x0 >;    /* in zephyr/dts/arm64/renesas/rz/rza/r9a07g063.dtsi:24 */

		/* node '/cpus/cpu@0' defined in zephyr/dts/arm64/renesas/rz/rza/r9a07g063.dtsi:26 */
		cpu@0 {
			device_type = "cpu";              /* in zephyr/dts/arm64/renesas/rz/rza/r9a07g063.dtsi:27 */
			compatible = "arm,cortex-a55";    /* in zephyr/dts/arm64/renesas/rz/rza/r9a07g063.dtsi:28 */
			clock-frequency = < 0x3b9aca00 >; /* in zephyr/dts/arm64/renesas/rz/rza/r9a07g063.dtsi:29 */
			reg = < 0x0 >;                    /* in zephyr/dts/arm64/renesas/rz/rza/r9a07g063.dtsi:30 */
		};
	};

	/* node '/timer' defined in zephyr/dts/arm64/renesas/rz/rza/r9a07g063.dtsi:34 */
	arch_timer: timer {
		compatible = "arm,armv8-timer";    /* in zephyr/dts/arm64/renesas/rz/rza/r9a07g063.dtsi:35 */
		interrupts = < 0x1 0xd 0x2 0xa0 >,
		             < 0x1 0xe 0x2 0xa0 >,
		             < 0x1 0xb 0x2 0xa0 >,
		             < 0x1 0xa 0x2 0xa0 >; /* in zephyr/dts/arm64/renesas/rz/rza/r9a07g063.dtsi:36 */
		interrupt-parent = < &gic >;       /* in zephyr/dts/arm64/renesas/rz/rza/r9a07g063.dtsi:40 */
	};

	/* node '/osc' defined in zephyr/dts/arm64/renesas/rz/rza/r9a07g063.dtsi:43 */
	osc: osc {
		compatible = "fixed-clock";      /* in zephyr/dts/arm64/renesas/rz/rza/r9a07g063.dtsi:44 */
		clock-frequency = < 0x16e3600 >; /* in zephyr/dts/arm64/renesas/rz/rza/r9a07g063.dtsi:45 */
		#clock-cells = < 0x0 >;          /* in zephyr/dts/arm64/renesas/rz/rza/r9a07g063.dtsi:46 */
		phandle = < 0x2 >;               /* in zephyr/dts/arm64/renesas/rz/rza/r9a07g063.dtsi:55 */
	};

	/* node '/memory@40200000' defined in zephyr/boards/renesas/rza3ul_smarc/rza3ul_smarc.dts:31 */
	ddr: memory@40200000 {
		compatible = "zephyr,memory-region",
		             "mmio-sram";            /* in zephyr/boards/renesas/rza3ul_smarc/rza3ul_smarc.dts:32 */
		reg = < 0x40200000 0x3fe00000 >;     /* in zephyr/boards/renesas/rza3ul_smarc/rza3ul_smarc.dts:33 */
		zephyr,memory-region = "DDR";        /* in zephyr/boards/renesas/rza3ul_smarc/rza3ul_smarc.dts:34 */
	};

	/* node '/memory@1e000' defined in zephyr/boards/renesas/rza3ul_smarc/rza3ul_smarc.dts:37 */
	sram: memory@1e000 {
		compatible = "zephyr,memory-region",
		             "mmio-sram";            /* in zephyr/boards/renesas/rza3ul_smarc/rza3ul_smarc.dts:38 */
		reg = < 0x1e000 0x12000 >;           /* in zephyr/boards/renesas/rza3ul_smarc/rza3ul_smarc.dts:39 */
		zephyr,memory-region = "SRAM";       /* in zephyr/boards/renesas/rza3ul_smarc/rza3ul_smarc.dts:40 */
	};
};
